VERSION ""

NS_ :

BS_:

BU_:

BO_ 2181387264 READ_PARAMETER_192_AND_193: 8 Vector__XXX
 SG_ FIRST_PARAMETER_VALUE : 0|32@1+ (1,0) [0|0] "" Vector__XXX
 SG_ SECOND_PARAMETER_VALUE : 32|32@1+ (1,0) [0|0] "" Vector__XXX

CM_ BO_ 2181387264 "Read parameter 192 and 193 at the same time. SPARK MAX does not currently support this in v25.0.0-prerelease.4";
CM_ SG_ 2181387264 FIRST_PARAMETER_VALUE "The actual type of this data depends on the Parameter Type of the parameter in question";
CM_ SG_ 2181387264 SECOND_PARAMETER_VALUE "The actual type of this data depends on the Parameter Type of the parameter in question";

BO_ 2181387328 READ_PARAMETER_194_AND_195: 8 Vector__XXX
 SG_ FIRST_PARAMETER_VALUE : 0|32@1+ (1,0) [0|0] "" Vector__XXX
 SG_ SECOND_PARAMETER_VALUE : 32|32@1+ (1,0) [0|0] "" Vector__XXX

CM_ BO_ 2181387328 "Read parameter 194 and 195 at the same time. SPARK MAX does not currently support this in v25.0.0-prerelease.4";
CM_ SG_ 2181387328 FIRST_PARAMETER_VALUE "The actual type of this data depends on the Parameter Type of the parameter in question";
CM_ SG_ 2181387328 SECOND_PARAMETER_VALUE "The actual type of this data depends on the Parameter Type of the parameter in question";

BO_ 2181387392 READ_PARAMETER_196_AND_197: 8 Vector__XXX
 SG_ FIRST_PARAMETER_VALUE : 0|32@1+ (1,0) [0|0] "" Vector__XXX
 SG_ SECOND_PARAMETER_VALUE : 32|32@1+ (1,0) [0|0] "" Vector__XXX

CM_ BO_ 2181387392 "Read parameter 196 and 197 at the same time. SPARK MAX does not currently support this in v25.0.0-prerelease.4";
CM_ SG_ 2181387392 FIRST_PARAMETER_VALUE "The actual type of this data depends on the Parameter Type of the parameter in question";
CM_ SG_ 2181387392 SECOND_PARAMETER_VALUE "The actual type of this data depends on the Parameter Type of the parameter in question";

BO_ 2181387456 READ_PARAMETER_198_AND_199: 8 Vector__XXX
 SG_ FIRST_PARAMETER_VALUE : 0|32@1+ (1,0) [0|0] "" Vector__XXX
 SG_ SECOND_PARAMETER_VALUE : 32|32@1+ (1,0) [0|0] "" Vector__XXX

CM_ BO_ 2181387456 "Read parameter 198 and 199 at the same time. SPARK MAX does not currently support this in v25.0.0-prerelease.4";
CM_ SG_ 2181387456 FIRST_PARAMETER_VALUE "The actual type of this data depends on the Parameter Type of the parameter in question";
CM_ SG_ 2181387456 SECOND_PARAMETER_VALUE "The actual type of this data depends on the Parameter Type of the parameter in question";

BO_ 2181387520 READ_PARAMETER_200_AND_201: 8 Vector__XXX
 SG_ FIRST_PARAMETER_VALUE : 0|32@1+ (1,0) [0|0] "" Vector__XXX
 SG_ SECOND_PARAMETER_VALUE : 32|32@1+ (1,0) [0|0] "" Vector__XXX

CM_ BO_ 2181387520 "Read parameter 200 and 201 at the same time. SPARK MAX does not currently support this in v25.0.0-prerelease.4";
CM_ SG_ 2181387520 FIRST_PARAMETER_VALUE "The actual type of this data depends on the Parameter Type of the parameter in question";
CM_ SG_ 2181387520 SECOND_PARAMETER_VALUE "The actual type of this data depends on the Parameter Type of the parameter in question";

BO_ 2181387584 READ_PARAMETER_202_AND_203: 8 Vector__XXX
 SG_ FIRST_PARAMETER_VALUE : 0|32@1+ (1,0) [0|0] "" Vector__XXX
 SG_ SECOND_PARAMETER_VALUE : 32|32@1+ (1,0) [0|0] "" Vector__XXX

CM_ BO_ 2181387584 "Read parameter 202 and 203 at the same time. SPARK MAX does not currently support this in v25.0.0-prerelease.4";
CM_ SG_ 2181387584 FIRST_PARAMETER_VALUE "The actual type of this data depends on the Parameter Type of the parameter in question";
CM_ SG_ 2181387584 SECOND_PARAMETER_VALUE "The actual type of this data depends on the Parameter Type of the parameter in question";

BO_ 2181387648 READ_PARAMETER_204_AND_205: 8 Vector__XXX
 SG_ FIRST_PARAMETER_VALUE : 0|32@1+ (1,0) [0|0] "" Vector__XXX
 SG_ SECOND_PARAMETER_VALUE : 32|32@1+ (1,0) [0|0] "" Vector__XXX

CM_ BO_ 2181387648 "Read parameter 204 and 205 at the same time. SPARK MAX does not currently support this in v25.0.0-prerelease.4";
CM_ SG_ 2181387648 FIRST_PARAMETER_VALUE "The actual type of this data depends on the Parameter Type of the parameter in question";
CM_ SG_ 2181387648 SECOND_PARAMETER_VALUE "The actual type of this data depends on the Parameter Type of the parameter in question";

BO_ 2181387712 READ_PARAMETER_206_AND_207: 8 Vector__XXX
 SG_ FIRST_PARAMETER_VALUE : 0|32@1+ (1,0) [0|0] "" Vector__XXX
 SG_ SECOND_PARAMETER_VALUE : 32|32@1+ (1,0) [0|0] "" Vector__XXX

CM_ BO_ 2181387712 "Read parameter 206 and 207 at the same time. SPARK MAX does not currently support this in v25.0.0-prerelease.4";
CM_ SG_ 2181387712 FIRST_PARAMETER_VALUE "The actual type of this data depends on the Parameter Type of the parameter in question";
CM_ SG_ 2181387712 SECOND_PARAMETER_VALUE "The actual type of this data depends on the Parameter Type of the parameter in question";

BO_ 2181387776 READ_PARAMETER_208_AND_209: 8 Vector__XXX
 SG_ FIRST_PARAMETER_VALUE : 0|32@1+ (1,0) [0|0] "" Vector__XXX
 SG_ SECOND_PARAMETER_VALUE : 32|32@1+ (1,0) [0|0] "" Vector__XXX

CM_ BO_ 2181387776 "Read parameter 208 and 209 at the same time. SPARK MAX does not currently support this in v25.0.0-prerelease.4";
CM_ SG_ 2181387776 FIRST_PARAMETER_VALUE "The actual type of this data depends on the Parameter Type of the parameter in question";
CM_ SG_ 2181387776 SECOND_PARAMETER_VALUE "The actual type of this data depends on the Parameter Type of the parameter in question";

BO_ 2181387840 READ_PARAMETER_210_AND_211: 8 Vector__XXX
 SG_ FIRST_PARAMETER_VALUE : 0|32@1+ (1,0) [0|0] "" Vector__XXX
 SG_ SECOND_PARAMETER_VALUE : 32|32@1+ (1,0) [0|0] "" Vector__XXX

CM_ BO_ 2181387840 "Read parameter 210 and 211 at the same time. SPARK MAX does not currently support this in v25.0.0-prerelease.4";
CM_ SG_ 2181387840 FIRST_PARAMETER_VALUE "The actual type of this data depends on the Parameter Type of the parameter in question";
CM_ SG_ 2181387840 SECOND_PARAMETER_VALUE "The actual type of this data depends on the Parameter Type of the parameter in question";

BO_ 2181387904 READ_PARAMETER_212_AND_213: 8 Vector__XXX
 SG_ FIRST_PARAMETER_VALUE : 0|32@1+ (1,0) [0|0] "" Vector__XXX
 SG_ SECOND_PARAMETER_VALUE : 32|32@1+ (1,0) [0|0] "" Vector__XXX

CM_ BO_ 2181387904 "Read parameter 212 and 213 at the same time. SPARK MAX does not currently support this in v25.0.0-prerelease.4";
CM_ SG_ 2181387904 FIRST_PARAMETER_VALUE "The actual type of this data depends on the Parameter Type of the parameter in question";
CM_ SG_ 2181387904 SECOND_PARAMETER_VALUE "The actual type of this data depends on the Parameter Type of the parameter in question";

BO_ 2181387968 READ_PARAMETER_214_AND_215: 8 Vector__XXX
 SG_ FIRST_PARAMETER_VALUE : 0|32@1+ (1,0) [0|0] "" Vector__XXX
 SG_ SECOND_PARAMETER_VALUE : 32|32@1+ (1,0) [0|0] "" Vector__XXX

CM_ BO_ 2181387968 "Read parameter 214 and 215 at the same time. SPARK MAX does not currently support this in v25.0.0-prerelease.4";
CM_ SG_ 2181387968 FIRST_PARAMETER_VALUE "The actual type of this data depends on the Parameter Type of the parameter in question";
CM_ SG_ 2181387968 SECOND_PARAMETER_VALUE "The actual type of this data depends on the Parameter Type of the parameter in question";

BO_ 2181388032 READ_PARAMETER_216_AND_217: 8 Vector__XXX
 SG_ FIRST_PARAMETER_VALUE : 0|32@1+ (1,0) [0|0] "" Vector__XXX
 SG_ SECOND_PARAMETER_VALUE : 32|32@1+ (1,0) [0|0] "" Vector__XXX

CM_ BO_ 2181388032 "Read parameter 216 and 217 at the same time. SPARK MAX does not currently support this in v25.0.0-prerelease.4";
CM_ SG_ 2181388032 FIRST_PARAMETER_VALUE "The actual type of this data depends on the Parameter Type of the parameter in question";
CM_ SG_ 2181388032 SECOND_PARAMETER_VALUE "The actual type of this data depends on the Parameter Type of the parameter in question";

BO_ 2181388096 READ_PARAMETER_218_AND_219: 8 Vector__XXX
 SG_ FIRST_PARAMETER_VALUE : 0|32@1+ (1,0) [0|0] "" Vector__XXX
 SG_ SECOND_PARAMETER_VALUE : 32|32@1+ (1,0) [0|0] "" Vector__XXX

CM_ BO_ 2181388096 "Read parameter 218 and 219 at the same time. SPARK MAX does not currently support this in v25.0.0-prerelease.4";
CM_ SG_ 2181388096 FIRST_PARAMETER_VALUE "The actual type of this data depends on the Parameter Type of the parameter in question";
CM_ SG_ 2181388096 SECOND_PARAMETER_VALUE "The actual type of this data depends on the Parameter Type of the parameter in question";

BO_ 2181388160 READ_PARAMETER_220_AND_221: 8 Vector__XXX
 SG_ FIRST_PARAMETER_VALUE : 0|32@1+ (1,0) [0|0] "" Vector__XXX
 SG_ SECOND_PARAMETER_VALUE : 32|32@1+ (1,0) [0|0] "" Vector__XXX

CM_ BO_ 2181388160 "Read parameter 220 and 221 at the same time. SPARK MAX does not currently support this in v25.0.0-prerelease.4";
CM_ SG_ 2181388160 FIRST_PARAMETER_VALUE "The actual type of this data depends on the Parameter Type of the parameter in question";
CM_ SG_ 2181388160 SECOND_PARAMETER_VALUE "The actual type of this data depends on the Parameter Type of the parameter in question";

BO_ 2181388224 READ_PARAMETER_222_AND_223: 8 Vector__XXX
 SG_ FIRST_PARAMETER_VALUE : 0|32@1+ (1,0) [0|0] "" Vector__XXX
 SG_ SECOND_PARAMETER_VALUE : 32|32@1+ (1,0) [0|0] "" Vector__XXX

CM_ BO_ 2181388224 "Read parameter 222 and 223 at the same time. SPARK MAX does not currently support this in v25.0.0-prerelease.4";
CM_ SG_ 2181388224 FIRST_PARAMETER_VALUE "The actual type of this data depends on the Parameter Type of the parameter in question";
CM_ SG_ 2181388224 SECOND_PARAMETER_VALUE "The actual type of this data depends on the Parameter Type of the parameter in question";

BO_ 2181388288 READ_PARAMETER_224_AND_225: 8 Vector__XXX
 SG_ FIRST_PARAMETER_VALUE : 0|32@1+ (1,0) [0|0] "" Vector__XXX
 SG_ SECOND_PARAMETER_VALUE : 32|32@1+ (1,0) [0|0] "" Vector__XXX

CM_ BO_ 2181388288 "Read parameter 224 and 225 at the same time. SPARK MAX does not currently support this in v25.0.0-prerelease.4";
CM_ SG_ 2181388288 FIRST_PARAMETER_VALUE "The actual type of this data depends on the Parameter Type of the parameter in question";
CM_ SG_ 2181388288 SECOND_PARAMETER_VALUE "The actual type of this data depends on the Parameter Type of the parameter in question";

BO_ 2181388352 READ_PARAMETER_226_AND_227: 8 Vector__XXX
 SG_ FIRST_PARAMETER_VALUE : 0|32@1+ (1,0) [0|0] "" Vector__XXX
 SG_ SECOND_PARAMETER_VALUE : 32|32@1+ (1,0) [0|0] "" Vector__XXX

CM_ BO_ 2181388352 "Read parameter 226 and 227 at the same time. SPARK MAX does not currently support this in v25.0.0-prerelease.4";
CM_ SG_ 2181388352 FIRST_PARAMETER_VALUE "The actual type of this data depends on the Parameter Type of the parameter in question";
CM_ SG_ 2181388352 SECOND_PARAMETER_VALUE "The actual type of this data depends on the Parameter Type of the parameter in question";

BO_ 2181388416 READ_PARAMETER_228_AND_229: 8 Vector__XXX
 SG_ FIRST_PARAMETER_VALUE : 0|32@1+ (1,0) [0|0] "" Vector__XXX
 SG_ SECOND_PARAMETER_VALUE : 32|32@1+ (1,0) [0|0] "" Vector__XXX

CM_ BO_ 2181388416 "Read parameter 228 and 229 at the same time. SPARK MAX does not currently support this in v25.0.0-prerelease.4";
CM_ SG_ 2181388416 FIRST_PARAMETER_VALUE "The actual type of this data depends on the Parameter Type of the parameter in question";
CM_ SG_ 2181388416 SECOND_PARAMETER_VALUE "The actual type of this data depends on the Parameter Type of the parameter in question";

BO_ 2181388480 READ_PARAMETER_230_AND_231: 8 Vector__XXX
 SG_ FIRST_PARAMETER_VALUE : 0|32@1+ (1,0) [0|0] "" Vector__XXX
 SG_ SECOND_PARAMETER_VALUE : 32|32@1+ (1,0) [0|0] "" Vector__XXX

CM_ BO_ 2181388480 "Read parameter 230 and 231 at the same time. SPARK MAX does not currently support this in v25.0.0-prerelease.4";
CM_ SG_ 2181388480 FIRST_PARAMETER_VALUE "The actual type of this data depends on the Parameter Type of the parameter in question";
CM_ SG_ 2181388480 SECOND_PARAMETER_VALUE "The actual type of this data depends on the Parameter Type of the parameter in question";

BO_ 2181388544 READ_PARAMETER_232_AND_233: 8 Vector__XXX
 SG_ FIRST_PARAMETER_VALUE : 0|32@1+ (1,0) [0|0] "" Vector__XXX
 SG_ SECOND_PARAMETER_VALUE : 32|32@1+ (1,0) [0|0] "" Vector__XXX

CM_ BO_ 2181388544 "Read parameter 232 and 233 at the same time. SPARK MAX does not currently support this in v25.0.0-prerelease.4";
CM_ SG_ 2181388544 FIRST_PARAMETER_VALUE "The actual type of this data depends on the Parameter Type of the parameter in question";
CM_ SG_ 2181388544 SECOND_PARAMETER_VALUE "The actual type of this data depends on the Parameter Type of the parameter in question";

BO_ 2181388608 READ_PARAMETER_234_AND_235: 8 Vector__XXX
 SG_ FIRST_PARAMETER_VALUE : 0|32@1+ (1,0) [0|0] "" Vector__XXX
 SG_ SECOND_PARAMETER_VALUE : 32|32@1+ (1,0) [0|0] "" Vector__XXX

CM_ BO_ 2181388608 "Read parameter 234 and 235 at the same time. SPARK MAX does not currently support this in v25.0.0-prerelease.4";
CM_ SG_ 2181388608 FIRST_PARAMETER_VALUE "The actual type of this data depends on the Parameter Type of the parameter in question";
CM_ SG_ 2181388608 SECOND_PARAMETER_VALUE "The actual type of this data depends on the Parameter Type of the parameter in question";

BO_ 2181388672 READ_PARAMETER_236_AND_237: 8 Vector__XXX
 SG_ FIRST_PARAMETER_VALUE : 0|32@1+ (1,0) [0|0] "" Vector__XXX
 SG_ SECOND_PARAMETER_VALUE : 32|32@1+ (1,0) [0|0] "" Vector__XXX

CM_ BO_ 2181388672 "Read parameter 236 and 237 at the same time. SPARK MAX does not currently support this in v25.0.0-prerelease.4";
CM_ SG_ 2181388672 FIRST_PARAMETER_VALUE "The actual type of this data depends on the Parameter Type of the parameter in question";
CM_ SG_ 2181388672 SECOND_PARAMETER_VALUE "The actual type of this data depends on the Parameter Type of the parameter in question";

BO_ 2181388736 READ_PARAMETER_238_AND_239: 8 Vector__XXX
 SG_ FIRST_PARAMETER_VALUE : 0|32@1+ (1,0) [0|0] "" Vector__XXX
 SG_ SECOND_PARAMETER_VALUE : 32|32@1+ (1,0) [0|0] "" Vector__XXX

CM_ BO_ 2181388736 "Read parameter 238 and 239 at the same time. SPARK MAX does not currently support this in v25.0.0-prerelease.4";
CM_ SG_ 2181388736 FIRST_PARAMETER_VALUE "The actual type of this data depends on the Parameter Type of the parameter in question";
CM_ SG_ 2181388736 SECOND_PARAMETER_VALUE "The actual type of this data depends on the Parameter Type of the parameter in question";

BO_ 2181388800 READ_PARAMETER_240_AND_241: 8 Vector__XXX
 SG_ FIRST_PARAMETER_VALUE : 0|32@1+ (1,0) [0|0] "" Vector__XXX
 SG_ SECOND_PARAMETER_VALUE : 32|32@1+ (1,0) [0|0] "" Vector__XXX

CM_ BO_ 2181388800 "Read parameter 240 and 241 at the same time. SPARK MAX does not currently support this in v25.0.0-prerelease.4";
CM_ SG_ 2181388800 FIRST_PARAMETER_VALUE "The actual type of this data depends on the Parameter Type of the parameter in question";
CM_ SG_ 2181388800 SECOND_PARAMETER_VALUE "The actual type of this data depends on the Parameter Type of the parameter in question";

BO_ 2181388864 READ_PARAMETER_242_AND_243: 8 Vector__XXX
 SG_ FIRST_PARAMETER_VALUE : 0|32@1+ (1,0) [0|0] "" Vector__XXX
 SG_ SECOND_PARAMETER_VALUE : 32|32@1+ (1,0) [0|0] "" Vector__XXX

CM_ BO_ 2181388864 "Read parameter 242 and 243 at the same time. SPARK MAX does not currently support this in v25.0.0-prerelease.4";
CM_ SG_ 2181388864 FIRST_PARAMETER_VALUE "The actual type of this data depends on the Parameter Type of the parameter in question";
CM_ SG_ 2181388864 SECOND_PARAMETER_VALUE "The actual type of this data depends on the Parameter Type of the parameter in question";

BO_ 2181388928 READ_PARAMETER_244_AND_245: 8 Vector__XXX
 SG_ FIRST_PARAMETER_VALUE : 0|32@1+ (1,0) [0|0] "" Vector__XXX
 SG_ SECOND_PARAMETER_VALUE : 32|32@1+ (1,0) [0|0] "" Vector__XXX

CM_ BO_ 2181388928 "Read parameter 244 and 245 at the same time. SPARK MAX does not currently support this in v25.0.0-prerelease.4";
CM_ SG_ 2181388928 FIRST_PARAMETER_VALUE "The actual type of this data depends on the Parameter Type of the parameter in question";
CM_ SG_ 2181388928 SECOND_PARAMETER_VALUE "The actual type of this data depends on the Parameter Type of the parameter in question";

BO_ 2181388992 READ_PARAMETER_246_AND_247: 8 Vector__XXX
 SG_ FIRST_PARAMETER_VALUE : 0|32@1+ (1,0) [0|0] "" Vector__XXX
 SG_ SECOND_PARAMETER_VALUE : 32|32@1+ (1,0) [0|0] "" Vector__XXX

CM_ BO_ 2181388992 "Read parameter 246 and 247 at the same time. SPARK MAX does not currently support this in v25.0.0-prerelease.4";
CM_ SG_ 2181388992 FIRST_PARAMETER_VALUE "The actual type of this data depends on the Parameter Type of the parameter in question";
CM_ SG_ 2181388992 SECOND_PARAMETER_VALUE "The actual type of this data depends on the Parameter Type of the parameter in question";

BO_ 2181389056 READ_PARAMETER_248_AND_249: 8 Vector__XXX
 SG_ FIRST_PARAMETER_VALUE : 0|32@1+ (1,0) [0|0] "" Vector__XXX
 SG_ SECOND_PARAMETER_VALUE : 32|32@1+ (1,0) [0|0] "" Vector__XXX

CM_ BO_ 2181389056 "Read parameter 248 and 249 at the same time. SPARK MAX does not currently support this in v25.0.0-prerelease.4";
CM_ SG_ 2181389056 FIRST_PARAMETER_VALUE "The actual type of this data depends on the Parameter Type of the parameter in question";
CM_ SG_ 2181389056 SECOND_PARAMETER_VALUE "The actual type of this data depends on the Parameter Type of the parameter in question";

BO_ 2181389120 READ_PARAMETER_250_AND_251: 8 Vector__XXX
 SG_ FIRST_PARAMETER_VALUE : 0|32@1+ (1,0) [0|0] "" Vector__XXX
 SG_ SECOND_PARAMETER_VALUE : 32|32@1+ (1,0) [0|0] "" Vector__XXX

CM_ BO_ 2181389120 "Read parameter 250 and 251 at the same time. SPARK MAX does not currently support this in v25.0.0-prerelease.4";
CM_ SG_ 2181389120 FIRST_PARAMETER_VALUE "The actual type of this data depends on the Parameter Type of the parameter in question";
CM_ SG_ 2181389120 SECOND_PARAMETER_VALUE "The actual type of this data depends on the Parameter Type of the parameter in question";

BO_ 2181389184 READ_PARAMETER_252_AND_253: 8 Vector__XXX
 SG_ FIRST_PARAMETER_VALUE : 0|32@1+ (1,0) [0|0] "" Vector__XXX
 SG_ SECOND_PARAMETER_VALUE : 32|32@1+ (1,0) [0|0] "" Vector__XXX

CM_ BO_ 2181389184 "Read parameter 252 and 253 at the same time. SPARK MAX does not currently support this in v25.0.0-prerelease.4";
CM_ SG_ 2181389184 FIRST_PARAMETER_VALUE "The actual type of this data depends on the Parameter Type of the parameter in question";
CM_ SG_ 2181389184 SECOND_PARAMETER_VALUE "The actual type of this data depends on the Parameter Type of the parameter in question";

BO_ 2181389248 READ_PARAMETER_254_AND_255: 8 Vector__XXX
 SG_ FIRST_PARAMETER_VALUE : 0|32@1+ (1,0) [0|0] "" Vector__XXX
 SG_ SECOND_PARAMETER_VALUE : 32|32@1+ (1,0) [0|0] "" Vector__XXX

CM_ BO_ 2181389248 "Read parameter 254 and 255 at the same time. SPARK MAX does not currently support this in v25.0.0-prerelease.4";
CM_ SG_ 2181389248 FIRST_PARAMETER_VALUE "The actual type of this data depends on the Parameter Type of the parameter in question";
CM_ SG_ 2181389248 SECOND_PARAMETER_VALUE "The actual type of this data depends on the Parameter Type of the parameter in question";

BO_ 2181389312 WRITE_PARAMETER_0_AND_1: 8 Vector__XXX
 SG_ FIRST_PARAMETER_VALUE : 0|32@1+ (1,0) [0|0] "" Vector__XXX
 SG_ SECOND_PARAMETER_VALUE : 32|32@1+ (1,0) [0|0] "" Vector__XXX

CM_ BO_ 2181389312 "Write Parameter 0 and 1 at the same time. Two Write Parameter Response frames will be sent in response.";
CM_ SG_ 2181389312 FIRST_PARAMETER_VALUE "The actual type of this data depends on the Parameter Type of the parameter in question";
CM_ SG_ 2181389312 SECOND_PARAMETER_VALUE "The actual type of this data depends on the Parameter Type of the parameter in question";

BO_ 2181389376 WRITE_PARAMETER_2_AND_3: 8 Vector__XXX
 SG_ FIRST_PARAMETER_VALUE : 0|32@1+ (1,0) [0|0] "" Vector__XXX
 SG_ SECOND_PARAMETER_VALUE : 32|32@1+ (1,0) [0|0] "" Vector__XXX

CM_ BO_ 2181389376 "Write Parameter 2 and 3 at the same time. Two Write Parameter Response frames will be sent in response.";
CM_ SG_ 2181389376 FIRST_PARAMETER_VALUE "The actual type of this data depends on the Parameter Type of the parameter in question";
CM_ SG_ 2181389376 SECOND_PARAMETER_VALUE "The actual type of this data depends on the Parameter Type of the parameter in question";

BO_ 2181389440 WRITE_PARAMETER_4_AND_5: 8 Vector__XXX
 SG_ FIRST_PARAMETER_VALUE : 0|32@1+ (1,0) [0|0] "" Vector__XXX
 SG_ SECOND_PARAMETER_VALUE : 32|32@1+ (1,0) [0|0] "" Vector__XXX

CM_ BO_ 2181389440 "Write Parameter 4 and 5 at the same time. Two Write Parameter Response frames will be sent in response.";
CM_ SG_ 2181389440 FIRST_PARAMETER_VALUE "The actual type of this data depends on the Parameter Type of the parameter in question";
CM_ SG_ 2181389440 SECOND_PARAMETER_VALUE "The actual type of this data depends on the Parameter Type of the parameter in question";

BO_ 2181389504 WRITE_PARAMETER_6_AND_7: 8 Vector__XXX
 SG_ FIRST_PARAMETER_VALUE : 0|32@1+ (1,0) [0|0] "" Vector__XXX
 SG_ SECOND_PARAMETER_VALUE : 32|32@1+ (1,0) [0|0] "" Vector__XXX

CM_ BO_ 2181389504 "Write Parameter 6 and 7 at the same time. Two Write Parameter Response frames will be sent in response.";
CM_ SG_ 2181389504 FIRST_PARAMETER_VALUE "The actual type of this data depends on the Parameter Type of the parameter in question";
CM_ SG_ 2181389504 SECOND_PARAMETER_VALUE "The actual type of this data depends on the Parameter Type of the parameter in question";

BO_ 2181389568 WRITE_PARAMETER_8_AND_9: 8 Vector__XXX
 SG_ FIRST_PARAMETER_VALUE : 0|32@1+ (1,0) [0|0] "" Vector__XXX
 SG_ SECOND_PARAMETER_VALUE : 32|32@1+ (1,0) [0|0] "" Vector__XXX

CM_ BO_ 2181389568 "Write Parameter 8 and 9 at the same time. Two Write Parameter Response frames will be sent in response.";
CM_ SG_ 2181389568 FIRST_PARAMETER_VALUE "The actual type of this data depends on the Parameter Type of the parameter in question";
CM_ SG_ 2181389568 SECOND_PARAMETER_VALUE "The actual type of this data depends on the Parameter Type of the parameter in question";

BO_ 2181389632 WRITE_PARAMETER_10_AND_11: 8 Vector__XXX
 SG_ FIRST_PARAMETER_VALUE : 0|32@1+ (1,0) [0|0] "" Vector__XXX
 SG_ SECOND_PARAMETER_VALUE : 32|32@1+ (1,0) [0|0] "" Vector__XXX

CM_ BO_ 2181389632 "Write Parameter 10 and 11 at the same time. Two Write Parameter Response frames will be sent in response.";
CM_ SG_ 2181389632 FIRST_PARAMETER_VALUE "The actual type of this data depends on the Parameter Type of the parameter in question";
CM_ SG_ 2181389632 SECOND_PARAMETER_VALUE "The actual type of this data depends on the Parameter Type of the parameter in question";

BO_ 2181389696 WRITE_PARAMETER_12_AND_13: 8 Vector__XXX
 SG_ FIRST_PARAMETER_VALUE : 0|32@1+ (1,0) [0|0] "" Vector__XXX
 SG_ SECOND_PARAMETER_VALUE : 32|32@1+ (1,0) [0|0] "" Vector__XXX

CM_ BO_ 2181389696 "Write Parameter 12 and 13 at the same time. Two Write Parameter Response frames will be sent in response.";
CM_ SG_ 2181389696 FIRST_PARAMETER_VALUE "The actual type of this data depends on the Parameter Type of the parameter in question";
CM_ SG_ 2181389696 SECOND_PARAMETER_VALUE "The actual type of this data depends on the Parameter Type of the parameter in question";

BO_ 2181389760 WRITE_PARAMETER_14_AND_15: 8 Vector__XXX
 SG_ FIRST_PARAMETER_VALUE : 0|32@1+ (1,0) [0|0] "" Vector__XXX
 SG_ SECOND_PARAMETER_VALUE : 32|32@1+ (1,0) [0|0] "" Vector__XXX

CM_ BO_ 2181389760 "Write Parameter 14 and 15 at the same time. Two Write Parameter Response frames will be sent in response.";
CM_ SG_ 2181389760 FIRST_PARAMETER_VALUE "The actual type of this data depends on the Parameter Type of the parameter in question";
CM_ SG_ 2181389760 SECOND_PARAMETER_VALUE "The actual type of this data depends on the Parameter Type of the parameter in question";

BO_ 2181389824 WRITE_PARAMETER_16_AND_17: 8 Vector__XXX
 SG_ FIRST_PARAMETER_VALUE : 0|32@1+ (1,0) [0|0] "" Vector__XXX
 SG_ SECOND_PARAMETER_VALUE : 32|32@1+ (1,0) [0|0] "" Vector__XXX

CM_ BO_ 2181389824 "Write Parameter 16 and 17 at the same time. Two Write Parameter Response frames will be sent in response.";
CM_ SG_ 2181389824 FIRST_PARAMETER_VALUE "The actual type of this data depends on the Parameter Type of the parameter in question";
CM_ SG_ 2181389824 SECOND_PARAMETER_VALUE "The actual type of this data depends on the Parameter Type of the parameter in question";

BO_ 2181389888 WRITE_PARAMETER_18_AND_19: 8 Vector__XXX
 SG_ FIRST_PARAMETER_VALUE : 0|32@1+ (1,0) [0|0] "" Vector__XXX
 SG_ SECOND_PARAMETER_VALUE : 32|32@1+ (1,0) [0|0] "" Vector__XXX

CM_ BO_ 2181389888 "Write Parameter 18 and 19 at the same time. Two Write Parameter Response frames will be sent in response.";
CM_ SG_ 2181389888 FIRST_PARAMETER_VALUE "The actual type of this data depends on the Parameter Type of the parameter in question";
CM_ SG_ 2181389888 SECOND_PARAMETER_VALUE "The actual type of this data depends on the Parameter Type of the parameter in question";

BO_ 2181389952 WRITE_PARAMETER_20_AND_21: 8 Vector__XXX
 SG_ FIRST_PARAMETER_VALUE : 0|32@1+ (1,0) [0|0] "" Vector__XXX
 SG_ SECOND_PARAMETER_VALUE : 32|32@1+ (1,0) [0|0] "" Vector__XXX

CM_ BO_ 2181389952 "Write Parameter 20 and 21 at the same time. Two Write Parameter Response frames will be sent in response.";
CM_ SG_ 2181389952 FIRST_PARAMETER_VALUE "The actual type of this data depends on the Parameter Type of the parameter in question";
CM_ SG_ 2181389952 SECOND_PARAMETER_VALUE "The actual type of this data depends on the Parameter Type of the parameter in question";

BO_ 2181390016 WRITE_PARAMETER_22_AND_23: 8 Vector__XXX
 SG_ FIRST_PARAMETER_VALUE : 0|32@1+ (1,0) [0|0] "" Vector__XXX
 SG_ SECOND_PARAMETER_VALUE : 32|32@1+ (1,0) [0|0] "" Vector__XXX

CM_ BO_ 2181390016 "Write Parameter 22 and 23 at the same time. Two Write Parameter Response frames will be sent in response.";
CM_ SG_ 2181390016 FIRST_PARAMETER_VALUE "The actual type of this data depends on the Parameter Type of the parameter in question";
CM_ SG_ 2181390016 SECOND_PARAMETER_VALUE "The actual type of this data depends on the Parameter Type of the parameter in question";

BO_ 2181390080 WRITE_PARAMETER_24_AND_25: 8 Vector__XXX
 SG_ FIRST_PARAMETER_VALUE : 0|32@1+ (1,0) [0|0] "" Vector__XXX
 SG_ SECOND_PARAMETER_VALUE : 32|32@1+ (1,0) [0|0] "" Vector__XXX

CM_ BO_ 2181390080 "Write Parameter 24 and 25 at the same time. Two Write Parameter Response frames will be sent in response.";
CM_ SG_ 2181390080 FIRST_PARAMETER_VALUE "The actual type of this data depends on the Parameter Type of the parameter in question";
CM_ SG_ 2181390080 SECOND_PARAMETER_VALUE "The actual type of this data depends on the Parameter Type of the parameter in question";

BO_ 2181390144 WRITE_PARAMETER_26_AND_27: 8 Vector__XXX
 SG_ FIRST_PARAMETER_VALUE : 0|32@1+ (1,0) [0|0] "" Vector__XXX
 SG_ SECOND_PARAMETER_VALUE : 32|32@1+ (1,0) [0|0] "" Vector__XXX

CM_ BO_ 2181390144 "Write Parameter 26 and 27 at the same time. Two Write Parameter Response frames will be sent in response.";
CM_ SG_ 2181390144 FIRST_PARAMETER_VALUE "The actual type of this data depends on the Parameter Type of the parameter in question";
CM_ SG_ 2181390144 SECOND_PARAMETER_VALUE "The actual type of this data depends on the Parameter Type of the parameter in question";

BO_ 2181390208 WRITE_PARAMETER_28_AND_29: 8 Vector__XXX
 SG_ FIRST_PARAMETER_VALUE : 0|32@1+ (1,0) [0|0] "" Vector__XXX
 SG_ SECOND_PARAMETER_VALUE : 32|32@1+ (1,0) [0|0] "" Vector__XXX

CM_ BO_ 2181390208 "Write Parameter 28 and 29 at the same time. Two Write Parameter Response frames will be sent in response.";
CM_ SG_ 2181390208 FIRST_PARAMETER_VALUE "The actual type of this data depends on the Parameter Type of the parameter in question";
CM_ SG_ 2181390208 SECOND_PARAMETER_VALUE "The actual type of this data depends on the Parameter Type of the parameter in question";

BO_ 2181390272 WRITE_PARAMETER_30_AND_31: 8 Vector__XXX
 SG_ FIRST_PARAMETER_VALUE : 0|32@1+ (1,0) [0|0] "" Vector__XXX
 SG_ SECOND_PARAMETER_VALUE : 32|32@1+ (1,0) [0|0] "" Vector__XXX

CM_ BO_ 2181390272 "Write Parameter 30 and 31 at the same time. Two Write Parameter Response frames will be sent in response.";
CM_ SG_ 2181390272 FIRST_PARAMETER_VALUE "The actual type of this data depends on the Parameter Type of the parameter in question";
CM_ SG_ 2181390272 SECOND_PARAMETER_VALUE "The actual type of this data depends on the Parameter Type of the parameter in question";

BO_ 2181390336 WRITE_PARAMETER_32_AND_33: 8 Vector__XXX
 SG_ FIRST_PARAMETER_VALUE : 0|32@1+ (1,0) [0|0] "" Vector__XXX
 SG_ SECOND_PARAMETER_VALUE : 32|32@1+ (1,0) [0|0] "" Vector__XXX

CM_ BO_ 2181390336 "Write Parameter 32 and 33 at the same time. Two Write Parameter Response frames will be sent in response.";
CM_ SG_ 2181390336 FIRST_PARAMETER_VALUE "The actual type of this data depends on the Parameter Type of the parameter in question";
CM_ SG_ 2181390336 SECOND_PARAMETER_VALUE "The actual type of this data depends on the Parameter Type of the parameter in question";

BO_ 2181390400 WRITE_PARAMETER_34_AND_35: 8 Vector__XXX
 SG_ FIRST_PARAMETER_VALUE : 0|32@1+ (1,0) [0|0] "" Vector__XXX
 SG_ SECOND_PARAMETER_VALUE : 32|32@1+ (1,0) [0|0] "" Vector__XXX

CM_ BO_ 2181390400 "Write Parameter 34 and 35 at the same time. Two Write Parameter Response frames will be sent in response.";
CM_ SG_ 2181390400 FIRST_PARAMETER_VALUE "The actual type of this data depends on the Parameter Type of the parameter in question";
CM_ SG_ 2181390400 SECOND_PARAMETER_VALUE "The actual type of this data depends on the Parameter Type of the parameter in question";

BO_ 2181390464 WRITE_PARAMETER_36_AND_37: 8 Vector__XXX
 SG_ FIRST_PARAMETER_VALUE : 0|32@1+ (1,0) [0|0] "" Vector__XXX
 SG_ SECOND_PARAMETER_VALUE : 32|32@1+ (1,0) [0|0] "" Vector__XXX

CM_ BO_ 2181390464 "Write Parameter 36 and 37 at the same time. Two Write Parameter Response frames will be sent in response.";
CM_ SG_ 2181390464 FIRST_PARAMETER_VALUE "The actual type of this data depends on the Parameter Type of the parameter in question";
CM_ SG_ 2181390464 SECOND_PARAMETER_VALUE "The actual type of this data depends on the Parameter Type of the parameter in question";

BO_ 2181390528 WRITE_PARAMETER_38_AND_39: 8 Vector__XXX
 SG_ FIRST_PARAMETER_VALUE : 0|32@1+ (1,0) [0|0] "" Vector__XXX
 SG_ SECOND_PARAMETER_VALUE : 32|32@1+ (1,0) [0|0] "" Vector__XXX

CM_ BO_ 2181390528 "Write Parameter 38 and 39 at the same time. Two Write Parameter Response frames will be sent in response.";
CM_ SG_ 2181390528 FIRST_PARAMETER_VALUE "The actual type of this data depends on the Parameter Type of the parameter in question";
CM_ SG_ 2181390528 SECOND_PARAMETER_VALUE "The actual type of this data depends on the Parameter Type of the parameter in question";

BO_ 2181390592 WRITE_PARAMETER_40_AND_41: 8 Vector__XXX
 SG_ FIRST_PARAMETER_VALUE : 0|32@1+ (1,0) [0|0] "" Vector__XXX
 SG_ SECOND_PARAMETER_VALUE : 32|32@1+ (1,0) [0|0] "" Vector__XXX

CM_ BO_ 2181390592 "Write Parameter 40 and 41 at the same time. Two Write Parameter Response frames will be sent in response.";
CM_ SG_ 2181390592 FIRST_PARAMETER_VALUE "The actual type of this data depends on the Parameter Type of the parameter in question";
CM_ SG_ 2181390592 SECOND_PARAMETER_VALUE "The actual type of this data depends on the Parameter Type of the parameter in question";

BO_ 2181390656 WRITE_PARAMETER_42_AND_43: 8 Vector__XXX
 SG_ FIRST_PARAMETER_VALUE : 0|32@1+ (1,0) [0|0] "" Vector__XXX
 SG_ SECOND_PARAMETER_VALUE : 32|32@1+ (1,0) [0|0] "" Vector__XXX

CM_ BO_ 2181390656 "Write Parameter 42 and 43 at the same time. Two Write Parameter Response frames will be sent in response.";
CM_ SG_ 2181390656 FIRST_PARAMETER_VALUE "The actual type of this data depends on the Parameter Type of the parameter in question";
CM_ SG_ 2181390656 SECOND_PARAMETER_VALUE "The actual type of this data depends on the Parameter Type of the parameter in question";

BO_ 2181390720 WRITE_PARAMETER_44_AND_45: 8 Vector__XXX
 SG_ FIRST_PARAMETER_VALUE : 0|32@1+ (1,0) [0|0] "" Vector__XXX
 SG_ SECOND_PARAMETER_VALUE : 32|32@1+ (1,0) [0|0] "" Vector__XXX

CM_ BO_ 2181390720 "Write Parameter 44 and 45 at the same time. Two Write Parameter Response frames will be sent in response.";
CM_ SG_ 2181390720 FIRST_PARAMETER_VALUE "The actual type of this data depends on the Parameter Type of the parameter in question";
CM_ SG_ 2181390720 SECOND_PARAMETER_VALUE "The actual type of this data depends on the Parameter Type of the parameter in question";

BO_ 2181390784 WRITE_PARAMETER_46_AND_47: 8 Vector__XXX
 SG_ FIRST_PARAMETER_VALUE : 0|32@1+ (1,0) [0|0] "" Vector__XXX
 SG_ SECOND_PARAMETER_VALUE : 32|32@1+ (1,0) [0|0] "" Vector__XXX

CM_ BO_ 2181390784 "Write Parameter 46 and 47 at the same time. Two Write Parameter Response frames will be sent in response.";
CM_ SG_ 2181390784 FIRST_PARAMETER_VALUE "The actual type of this data depends on the Parameter Type of the parameter in question";
CM_ SG_ 2181390784 SECOND_PARAMETER_VALUE "The actual type of this data depends on the Parameter Type of the parameter in question";

BO_ 2181390848 WRITE_PARAMETER_48_AND_49: 8 Vector__XXX
 SG_ FIRST_PARAMETER_VALUE : 0|32@1+ (1,0) [0|0] "" Vector__XXX
 SG_ SECOND_PARAMETER_VALUE : 32|32@1+ (1,0) [0|0] "" Vector__XXX

CM_ BO_ 2181390848 "Write Parameter 48 and 49 at the same time. Two Write Parameter Response frames will be sent in response.";
CM_ SG_ 2181390848 FIRST_PARAMETER_VALUE "The actual type of this data depends on the Parameter Type of the parameter in question";
CM_ SG_ 2181390848 SECOND_PARAMETER_VALUE "The actual type of this data depends on the Parameter Type of the parameter in question";

BO_ 2181390912 WRITE_PARAMETER_50_AND_51: 8 Vector__XXX
 SG_ FIRST_PARAMETER_VALUE : 0|32@1+ (1,0) [0|0] "" Vector__XXX
 SG_ SECOND_PARAMETER_VALUE : 32|32@1+ (1,0) [0|0] "" Vector__XXX

CM_ BO_ 2181390912 "Write Parameter 50 and 51 at the same time. Two Write Parameter Response frames will be sent in response.";
CM_ SG_ 2181390912 FIRST_PARAMETER_VALUE "The actual type of this data depends on the Parameter Type of the parameter in question";
CM_ SG_ 2181390912 SECOND_PARAMETER_VALUE "The actual type of this data depends on the Parameter Type of the parameter in question";

BO_ 2181390976 WRITE_PARAMETER_52_AND_53: 8 Vector__XXX
 SG_ FIRST_PARAMETER_VALUE : 0|32@1+ (1,0) [0|0] "" Vector__XXX
 SG_ SECOND_PARAMETER_VALUE : 32|32@1+ (1,0) [0|0] "" Vector__XXX

CM_ BO_ 2181390976 "Write Parameter 52 and 53 at the same time. Two Write Parameter Response frames will be sent in response.";
CM_ SG_ 2181390976 FIRST_PARAMETER_VALUE "The actual type of this data depends on the Parameter Type of the parameter in question";
CM_ SG_ 2181390976 SECOND_PARAMETER_VALUE "The actual type of this data depends on the Parameter Type of the parameter in question";

BO_ 2181391040 WRITE_PARAMETER_54_AND_55: 8 Vector__XXX
 SG_ FIRST_PARAMETER_VALUE : 0|32@1+ (1,0) [0|0] "" Vector__XXX
 SG_ SECOND_PARAMETER_VALUE : 32|32@1+ (1,0) [0|0] "" Vector__XXX

CM_ BO_ 2181391040 "Write Parameter 54 and 55 at the same time. Two Write Parameter Response frames will be sent in response.";
CM_ SG_ 2181391040 FIRST_PARAMETER_VALUE "The actual type of this data depends on the Parameter Type of the parameter in question";
CM_ SG_ 2181391040 SECOND_PARAMETER_VALUE "The actual type of this data depends on the Parameter Type of the parameter in question";

BO_ 2181391104 WRITE_PARAMETER_56_AND_57: 8 Vector__XXX
 SG_ FIRST_PARAMETER_VALUE : 0|32@1+ (1,0) [0|0] "" Vector__XXX
 SG_ SECOND_PARAMETER_VALUE : 32|32@1+ (1,0) [0|0] "" Vector__XXX

CM_ BO_ 2181391104 "Write Parameter 56 and 57 at the same time. Two Write Parameter Response frames will be sent in response.";
CM_ SG_ 2181391104 FIRST_PARAMETER_VALUE "The actual type of this data depends on the Parameter Type of the parameter in question";
CM_ SG_ 2181391104 SECOND_PARAMETER_VALUE "The actual type of this data depends on the Parameter Type of the parameter in question";

BO_ 2181391168 WRITE_PARAMETER_58_AND_59: 8 Vector__XXX
 SG_ FIRST_PARAMETER_VALUE : 0|32@1+ (1,0) [0|0] "" Vector__XXX
 SG_ SECOND_PARAMETER_VALUE : 32|32@1+ (1,0) [0|0] "" Vector__XXX

CM_ BO_ 2181391168 "Write Parameter 58 and 59 at the same time. Two Write Parameter Response frames will be sent in response.";
CM_ SG_ 2181391168 FIRST_PARAMETER_VALUE "The actual type of this data depends on the Parameter Type of the parameter in question";
CM_ SG_ 2181391168 SECOND_PARAMETER_VALUE "The actual type of this data depends on the Parameter Type of the parameter in question";

BO_ 2181391232 WRITE_PARAMETER_60_AND_61: 8 Vector__XXX
 SG_ FIRST_PARAMETER_VALUE : 0|32@1+ (1,0) [0|0] "" Vector__XXX
 SG_ SECOND_PARAMETER_VALUE : 32|32@1+ (1,0) [0|0] "" Vector__XXX

CM_ BO_ 2181391232 "Write Parameter 60 and 61 at the same time. Two Write Parameter Response frames will be sent in response.";
CM_ SG_ 2181391232 FIRST_PARAMETER_VALUE "The actual type of this data depends on the Parameter Type of the parameter in question";
CM_ SG_ 2181391232 SECOND_PARAMETER_VALUE "The actual type of this data depends on the Parameter Type of the parameter in question";

BO_ 2181391296 WRITE_PARAMETER_62_AND_63: 8 Vector__XXX
 SG_ FIRST_PARAMETER_VALUE : 0|32@1+ (1,0) [0|0] "" Vector__XXX
 SG_ SECOND_PARAMETER_VALUE : 32|32@1+ (1,0) [0|0] "" Vector__XXX

CM_ BO_ 2181391296 "Write Parameter 62 and 63 at the same time. Two Write Parameter Response frames will be sent in response.";
CM_ SG_ 2181391296 FIRST_PARAMETER_VALUE "The actual type of this data depends on the Parameter Type of the parameter in question";
CM_ SG_ 2181391296 SECOND_PARAMETER_VALUE "The actual type of this data depends on the Parameter Type of the parameter in question";

BO_ 2181391360 WRITE_PARAMETER_64_AND_65: 8 Vector__XXX
 SG_ FIRST_PARAMETER_VALUE : 0|32@1+ (1,0) [0|0] "" Vector__XXX
 SG_ SECOND_PARAMETER_VALUE : 32|32@1+ (1,0) [0|0] "" Vector__XXX

CM_ BO_ 2181391360 "Write Parameter 64 and 65 at the same time. Two Write Parameter Response frames will be sent in response.";
CM_ SG_ 2181391360 FIRST_PARAMETER_VALUE "The actual type of this data depends on the Parameter Type of the parameter in question";
CM_ SG_ 2181391360 SECOND_PARAMETER_VALUE "The actual type of this data depends on the Parameter Type of the parameter in question";

BO_ 2181391424 WRITE_PARAMETER_66_AND_67: 8 Vector__XXX
 SG_ FIRST_PARAMETER_VALUE : 0|32@1+ (1,0) [0|0] "" Vector__XXX
 SG_ SECOND_PARAMETER_VALUE : 32|32@1+ (1,0) [0|0] "" Vector__XXX

CM_ BO_ 2181391424 "Write Parameter 66 and 67 at the same time. Two Write Parameter Response frames will be sent in response.";
CM_ SG_ 2181391424 FIRST_PARAMETER_VALUE "The actual type of this data depends on the Parameter Type of the parameter in question";
CM_ SG_ 2181391424 SECOND_PARAMETER_VALUE "The actual type of this data depends on the Parameter Type of the parameter in question";

BO_ 2181391488 WRITE_PARAMETER_68_AND_69: 8 Vector__XXX
 SG_ FIRST_PARAMETER_VALUE : 0|32@1+ (1,0) [0|0] "" Vector__XXX
 SG_ SECOND_PARAMETER_VALUE : 32|32@1+ (1,0) [0|0] "" Vector__XXX

CM_ BO_ 2181391488 "Write Parameter 68 and 69 at the same time. Two Write Parameter Response frames will be sent in response.";
CM_ SG_ 2181391488 FIRST_PARAMETER_VALUE "The actual type of this data depends on the Parameter Type of the parameter in question";
CM_ SG_ 2181391488 SECOND_PARAMETER_VALUE "The actual type of this data depends on the Parameter Type of the parameter in question";

BO_ 2181391552 WRITE_PARAMETER_70_AND_71: 8 Vector__XXX
 SG_ FIRST_PARAMETER_VALUE : 0|32@1+ (1,0) [0|0] "" Vector__XXX
 SG_ SECOND_PARAMETER_VALUE : 32|32@1+ (1,0) [0|0] "" Vector__XXX

CM_ BO_ 2181391552 "Write Parameter 70 and 71 at the same time. Two Write Parameter Response frames will be sent in response.";
CM_ SG_ 2181391552 FIRST_PARAMETER_VALUE "The actual type of this data depends on the Parameter Type of the parameter in question";
CM_ SG_ 2181391552 SECOND_PARAMETER_VALUE "The actual type of this data depends on the Parameter Type of the parameter in question";

BO_ 2181391616 WRITE_PARAMETER_72_AND_73: 8 Vector__XXX
 SG_ FIRST_PARAMETER_VALUE : 0|32@1+ (1,0) [0|0] "" Vector__XXX
 SG_ SECOND_PARAMETER_VALUE : 32|32@1+ (1,0) [0|0] "" Vector__XXX

CM_ BO_ 2181391616 "Write Parameter 72 and 73 at the same time. Two Write Parameter Response frames will be sent in response.";
CM_ SG_ 2181391616 FIRST_PARAMETER_VALUE "The actual type of this data depends on the Parameter Type of the parameter in question";
CM_ SG_ 2181391616 SECOND_PARAMETER_VALUE "The actual type of this data depends on the Parameter Type of the parameter in question";

BO_ 2181391680 WRITE_PARAMETER_74_AND_75: 8 Vector__XXX
 SG_ FIRST_PARAMETER_VALUE : 0|32@1+ (1,0) [0|0] "" Vector__XXX
 SG_ SECOND_PARAMETER_VALUE : 32|32@1+ (1,0) [0|0] "" Vector__XXX

CM_ BO_ 2181391680 "Write Parameter 74 and 75 at the same time. Two Write Parameter Response frames will be sent in response.";
CM_ SG_ 2181391680 FIRST_PARAMETER_VALUE "The actual type of this data depends on the Parameter Type of the parameter in question";
CM_ SG_ 2181391680 SECOND_PARAMETER_VALUE "The actual type of this data depends on the Parameter Type of the parameter in question";

BO_ 2181391744 WRITE_PARAMETER_76_AND_77: 8 Vector__XXX
 SG_ FIRST_PARAMETER_VALUE : 0|32@1+ (1,0) [0|0] "" Vector__XXX
 SG_ SECOND_PARAMETER_VALUE : 32|32@1+ (1,0) [0|0] "" Vector__XXX

CM_ BO_ 2181391744 "Write Parameter 76 and 77 at the same time. Two Write Parameter Response frames will be sent in response.";
CM_ SG_ 2181391744 FIRST_PARAMETER_VALUE "The actual type of this data depends on the Parameter Type of the parameter in question";
CM_ SG_ 2181391744 SECOND_PARAMETER_VALUE "The actual type of this data depends on the Parameter Type of the parameter in question";

BO_ 2181391808 WRITE_PARAMETER_78_AND_79: 8 Vector__XXX
 SG_ FIRST_PARAMETER_VALUE : 0|32@1+ (1,0) [0|0] "" Vector__XXX
 SG_ SECOND_PARAMETER_VALUE : 32|32@1+ (1,0) [0|0] "" Vector__XXX

CM_ BO_ 2181391808 "Write Parameter 78 and 79 at the same time. Two Write Parameter Response frames will be sent in response.";
CM_ SG_ 2181391808 FIRST_PARAMETER_VALUE "The actual type of this data depends on the Parameter Type of the parameter in question";
CM_ SG_ 2181391808 SECOND_PARAMETER_VALUE "The actual type of this data depends on the Parameter Type of the parameter in question";

BO_ 2181391872 WRITE_PARAMETER_80_AND_81: 8 Vector__XXX
 SG_ FIRST_PARAMETER_VALUE : 0|32@1+ (1,0) [0|0] "" Vector__XXX
 SG_ SECOND_PARAMETER_VALUE : 32|32@1+ (1,0) [0|0] "" Vector__XXX

CM_ BO_ 2181391872 "Write Parameter 80 and 81 at the same time. Two Write Parameter Response frames will be sent in response.";
CM_ SG_ 2181391872 FIRST_PARAMETER_VALUE "The actual type of this data depends on the Parameter Type of the parameter in question";
CM_ SG_ 2181391872 SECOND_PARAMETER_VALUE "The actual type of this data depends on the Parameter Type of the parameter in question";

BO_ 2181391936 WRITE_PARAMETER_82_AND_83: 8 Vector__XXX
 SG_ FIRST_PARAMETER_VALUE : 0|32@1+ (1,0) [0|0] "" Vector__XXX
 SG_ SECOND_PARAMETER_VALUE : 32|32@1+ (1,0) [0|0] "" Vector__XXX

CM_ BO_ 2181391936 "Write Parameter 82 and 83 at the same time. Two Write Parameter Response frames will be sent in response.";
CM_ SG_ 2181391936 FIRST_PARAMETER_VALUE "The actual type of this data depends on the Parameter Type of the parameter in question";
CM_ SG_ 2181391936 SECOND_PARAMETER_VALUE "The actual type of this data depends on the Parameter Type of the parameter in question";

BO_ 2181392000 WRITE_PARAMETER_84_AND_85: 8 Vector__XXX
 SG_ FIRST_PARAMETER_VALUE : 0|32@1+ (1,0) [0|0] "" Vector__XXX
 SG_ SECOND_PARAMETER_VALUE : 32|32@1+ (1,0) [0|0] "" Vector__XXX

CM_ BO_ 2181392000 "Write Parameter 84 and 85 at the same time. Two Write Parameter Response frames will be sent in response.";
CM_ SG_ 2181392000 FIRST_PARAMETER_VALUE "The actual type of this data depends on the Parameter Type of the parameter in question";
CM_ SG_ 2181392000 SECOND_PARAMETER_VALUE "The actual type of this data depends on the Parameter Type of the parameter in question";

BO_ 2181392064 WRITE_PARAMETER_86_AND_87: 8 Vector__XXX
 SG_ FIRST_PARAMETER_VALUE : 0|32@1+ (1,0) [0|0] "" Vector__XXX
 SG_ SECOND_PARAMETER_VALUE : 32|32@1+ (1,0) [0|0] "" Vector__XXX

CM_ BO_ 2181392064 "Write Parameter 86 and 87 at the same time. Two Write Parameter Response frames will be sent in response.";
CM_ SG_ 2181392064 FIRST_PARAMETER_VALUE "The actual type of this data depends on the Parameter Type of the parameter in question";
CM_ SG_ 2181392064 SECOND_PARAMETER_VALUE "The actual type of this data depends on the Parameter Type of the parameter in question";

BO_ 2181392128 WRITE_PARAMETER_88_AND_89: 8 Vector__XXX
 SG_ FIRST_PARAMETER_VALUE : 0|32@1+ (1,0) [0|0] "" Vector__XXX
 SG_ SECOND_PARAMETER_VALUE : 32|32@1+ (1,0) [0|0] "" Vector__XXX

CM_ BO_ 2181392128 "Write Parameter 88 and 89 at the same time. Two Write Parameter Response frames will be sent in response.";
CM_ SG_ 2181392128 FIRST_PARAMETER_VALUE "The actual type of this data depends on the Parameter Type of the parameter in question";
CM_ SG_ 2181392128 SECOND_PARAMETER_VALUE "The actual type of this data depends on the Parameter Type of the parameter in question";

BO_ 2181392192 WRITE_PARAMETER_90_AND_91: 8 Vector__XXX
 SG_ FIRST_PARAMETER_VALUE : 0|32@1+ (1,0) [0|0] "" Vector__XXX
 SG_ SECOND_PARAMETER_VALUE : 32|32@1+ (1,0) [0|0] "" Vector__XXX

CM_ BO_ 2181392192 "Write Parameter 90 and 91 at the same time. Two Write Parameter Response frames will be sent in response.";
CM_ SG_ 2181392192 FIRST_PARAMETER_VALUE "The actual type of this data depends on the Parameter Type of the parameter in question";
CM_ SG_ 2181392192 SECOND_PARAMETER_VALUE "The actual type of this data depends on the Parameter Type of the parameter in question";

BO_ 2181392256 WRITE_PARAMETER_92_AND_93: 8 Vector__XXX
 SG_ FIRST_PARAMETER_VALUE : 0|32@1+ (1,0) [0|0] "" Vector__XXX
 SG_ SECOND_PARAMETER_VALUE : 32|32@1+ (1,0) [0|0] "" Vector__XXX

CM_ BO_ 2181392256 "Write Parameter 92 and 93 at the same time. Two Write Parameter Response frames will be sent in response.";
CM_ SG_ 2181392256 FIRST_PARAMETER_VALUE "The actual type of this data depends on the Parameter Type of the parameter in question";
CM_ SG_ 2181392256 SECOND_PARAMETER_VALUE "The actual type of this data depends on the Parameter Type of the parameter in question";

BO_ 2181392320 WRITE_PARAMETER_94_AND_95: 8 Vector__XXX
 SG_ FIRST_PARAMETER_VALUE : 0|32@1+ (1,0) [0|0] "" Vector__XXX
 SG_ SECOND_PARAMETER_VALUE : 32|32@1+ (1,0) [0|0] "" Vector__XXX

CM_ BO_ 2181392320 "Write Parameter 94 and 95 at the same time. Two Write Parameter Response frames will be sent in response.";
CM_ SG_ 2181392320 FIRST_PARAMETER_VALUE "The actual type of this data depends on the Parameter Type of the parameter in question";
CM_ SG_ 2181392320 SECOND_PARAMETER_VALUE "The actual type of this data depends on the Parameter Type of the parameter in question";

BO_ 2181392384 WRITE_PARAMETER_96_AND_97: 8 Vector__XXX
 SG_ FIRST_PARAMETER_VALUE : 0|32@1+ (1,0) [0|0] "" Vector__XXX
 SG_ SECOND_PARAMETER_VALUE : 32|32@1+ (1,0) [0|0] "" Vector__XXX

CM_ BO_ 2181392384 "Write Parameter 96 and 97 at the same time. Two Write Parameter Response frames will be sent in response.";
CM_ SG_ 2181392384 FIRST_PARAMETER_VALUE "The actual type of this data depends on the Parameter Type of the parameter in question";
CM_ SG_ 2181392384 SECOND_PARAMETER_VALUE "The actual type of this data depends on the Parameter Type of the parameter in question";

BO_ 2181392448 WRITE_PARAMETER_98_AND_99: 8 Vector__XXX
 SG_ FIRST_PARAMETER_VALUE : 0|32@1+ (1,0) [0|0] "" Vector__XXX
 SG_ SECOND_PARAMETER_VALUE : 32|32@1+ (1,0) [0|0] "" Vector__XXX

CM_ BO_ 2181392448 "Write Parameter 98 and 99 at the same time. Two Write Parameter Response frames will be sent in response.";
CM_ SG_ 2181392448 FIRST_PARAMETER_VALUE "The actual type of this data depends on the Parameter Type of the parameter in question";
CM_ SG_ 2181392448 SECOND_PARAMETER_VALUE "The actual type of this data depends on the Parameter Type of the parameter in question";

BO_ 2181392512 WRITE_PARAMETER_100_AND_101: 8 Vector__XXX
 SG_ FIRST_PARAMETER_VALUE : 0|32@1+ (1,0) [0|0] "" Vector__XXX
 SG_ SECOND_PARAMETER_VALUE : 32|32@1+ (1,0) [0|0] "" Vector__XXX

CM_ BO_ 2181392512 "Write Parameter 100 and 101 at the same time. Two Write Parameter Response frames will be sent in response.";
CM_ SG_ 2181392512 FIRST_PARAMETER_VALUE "The actual type of this data depends on the Parameter Type of the parameter in question";
CM_ SG_ 2181392512 SECOND_PARAMETER_VALUE "The actual type of this data depends on the Parameter Type of the parameter in question";

BO_ 2181392576 WRITE_PARAMETER_102_AND_103: 8 Vector__XXX
 SG_ FIRST_PARAMETER_VALUE : 0|32@1+ (1,0) [0|0] "" Vector__XXX
 SG_ SECOND_PARAMETER_VALUE : 32|32@1+ (1,0) [0|0] "" Vector__XXX

CM_ BO_ 2181392576 "Write Parameter 102 and 103 at the same time. Two Write Parameter Response frames will be sent in response.";
CM_ SG_ 2181392576 FIRST_PARAMETER_VALUE "The actual type of this data depends on the Parameter Type of the parameter in question";
CM_ SG_ 2181392576 SECOND_PARAMETER_VALUE "The actual type of this data depends on the Parameter Type of the parameter in question";

BO_ 2181392640 WRITE_PARAMETER_104_AND_105: 8 Vector__XXX
 SG_ FIRST_PARAMETER_VALUE : 0|32@1+ (1,0) [0|0] "" Vector__XXX
 SG_ SECOND_PARAMETER_VALUE : 32|32@1+ (1,0) [0|0] "" Vector__XXX

CM_ BO_ 2181392640 "Write Parameter 104 and 105 at the same time. Two Write Parameter Response frames will be sent in response.";
CM_ SG_ 2181392640 FIRST_PARAMETER_VALUE "The actual type of this data depends on the Parameter Type of the parameter in question";
CM_ SG_ 2181392640 SECOND_PARAMETER_VALUE "The actual type of this data depends on the Parameter Type of the parameter in question";

BO_ 2181392704 WRITE_PARAMETER_106_AND_107: 8 Vector__XXX
 SG_ FIRST_PARAMETER_VALUE : 0|32@1+ (1,0) [0|0] "" Vector__XXX
 SG_ SECOND_PARAMETER_VALUE : 32|32@1+ (1,0) [0|0] "" Vector__XXX

CM_ BO_ 2181392704 "Write Parameter 106 and 107 at the same time. Two Write Parameter Response frames will be sent in response.";
CM_ SG_ 2181392704 FIRST_PARAMETER_VALUE "The actual type of this data depends on the Parameter Type of the parameter in question";
CM_ SG_ 2181392704 SECOND_PARAMETER_VALUE "The actual type of this data depends on the Parameter Type of the parameter in question";

BO_ 2181392768 WRITE_PARAMETER_108_AND_109: 8 Vector__XXX
 SG_ FIRST_PARAMETER_VALUE : 0|32@1+ (1,0) [0|0] "" Vector__XXX
 SG_ SECOND_PARAMETER_VALUE : 32|32@1+ (1,0) [0|0] "" Vector__XXX

CM_ BO_ 2181392768 "Write Parameter 108 and 109 at the same time. Two Write Parameter Response frames will be sent in response.";
CM_ SG_ 2181392768 FIRST_PARAMETER_VALUE "The actual type of this data depends on the Parameter Type of the parameter in question";
CM_ SG_ 2181392768 SECOND_PARAMETER_VALUE "The actual type of this data depends on the Parameter Type of the parameter in question";

BO_ 2181392832 WRITE_PARAMETER_110_AND_111: 8 Vector__XXX
 SG_ FIRST_PARAMETER_VALUE : 0|32@1+ (1,0) [0|0] "" Vector__XXX
 SG_ SECOND_PARAMETER_VALUE : 32|32@1+ (1,0) [0|0] "" Vector__XXX

CM_ BO_ 2181392832 "Write Parameter 110 and 111 at the same time. Two Write Parameter Response frames will be sent in response.";
CM_ SG_ 2181392832 FIRST_PARAMETER_VALUE "The actual type of this data depends on the Parameter Type of the parameter in question";
CM_ SG_ 2181392832 SECOND_PARAMETER_VALUE "The actual type of this data depends on the Parameter Type of the parameter in question";

BO_ 2181392896 WRITE_PARAMETER_112_AND_113: 8 Vector__XXX
 SG_ FIRST_PARAMETER_VALUE : 0|32@1+ (1,0) [0|0] "" Vector__XXX
 SG_ SECOND_PARAMETER_VALUE : 32|32@1+ (1,0) [0|0] "" Vector__XXX

CM_ BO_ 2181392896 "Write Parameter 112 and 113 at the same time. Two Write Parameter Response frames will be sent in response.";
CM_ SG_ 2181392896 FIRST_PARAMETER_VALUE "The actual type of this data depends on the Parameter Type of the parameter in question";
CM_ SG_ 2181392896 SECOND_PARAMETER_VALUE "The actual type of this data depends on the Parameter Type of the parameter in question";

BO_ 2181392960 WRITE_PARAMETER_114_AND_115: 8 Vector__XXX
 SG_ FIRST_PARAMETER_VALUE : 0|32@1+ (1,0) [0|0] "" Vector__XXX
 SG_ SECOND_PARAMETER_VALUE : 32|32@1+ (1,0) [0|0] "" Vector__XXX

CM_ BO_ 2181392960 "Write Parameter 114 and 115 at the same time. Two Write Parameter Response frames will be sent in response.";
CM_ SG_ 2181392960 FIRST_PARAMETER_VALUE "The actual type of this data depends on the Parameter Type of the parameter in question";
CM_ SG_ 2181392960 SECOND_PARAMETER_VALUE "The actual type of this data depends on the Parameter Type of the parameter in question";

BO_ 2181393024 WRITE_PARAMETER_116_AND_117: 8 Vector__XXX
 SG_ FIRST_PARAMETER_VALUE : 0|32@1+ (1,0) [0|0] "" Vector__XXX
 SG_ SECOND_PARAMETER_VALUE : 32|32@1+ (1,0) [0|0] "" Vector__XXX

CM_ BO_ 2181393024 "Write Parameter 116 and 117 at the same time. Two Write Parameter Response frames will be sent in response.";
CM_ SG_ 2181393024 FIRST_PARAMETER_VALUE "The actual type of this data depends on the Parameter Type of the parameter in question";
CM_ SG_ 2181393024 SECOND_PARAMETER_VALUE "The actual type of this data depends on the Parameter Type of the parameter in question";

BO_ 2181393088 WRITE_PARAMETER_118_AND_119: 8 Vector__XXX
 SG_ FIRST_PARAMETER_VALUE : 0|32@1+ (1,0) [0|0] "" Vector__XXX
 SG_ SECOND_PARAMETER_VALUE : 32|32@1+ (1,0) [0|0] "" Vector__XXX

CM_ BO_ 2181393088 "Write Parameter 118 and 119 at the same time. Two Write Parameter Response frames will be sent in response.";
CM_ SG_ 2181393088 FIRST_PARAMETER_VALUE "The actual type of this data depends on the Parameter Type of the parameter in question";
CM_ SG_ 2181393088 SECOND_PARAMETER_VALUE "The actual type of this data depends on the Parameter Type of the parameter in question";

BO_ 2181393152 WRITE_PARAMETER_120_AND_121: 8 Vector__XXX
 SG_ FIRST_PARAMETER_VALUE : 0|32@1+ (1,0) [0|0] "" Vector__XXX
 SG_ SECOND_PARAMETER_VALUE : 32|32@1+ (1,0) [0|0] "" Vector__XXX

CM_ BO_ 2181393152 "Write Parameter 120 and 121 at the same time. Two Write Parameter Response frames will be sent in response.";
CM_ SG_ 2181393152 FIRST_PARAMETER_VALUE "The actual type of this data depends on the Parameter Type of the parameter in question";
CM_ SG_ 2181393152 SECOND_PARAMETER_VALUE "The actual type of this data depends on the Parameter Type of the parameter in question";

BO_ 2181393216 WRITE_PARAMETER_122_AND_123: 8 Vector__XXX
 SG_ FIRST_PARAMETER_VALUE : 0|32@1+ (1,0) [0|0] "" Vector__XXX
 SG_ SECOND_PARAMETER_VALUE : 32|32@1+ (1,0) [0|0] "" Vector__XXX

CM_ BO_ 2181393216 "Write Parameter 122 and 123 at the same time. Two Write Parameter Response frames will be sent in response.";
CM_ SG_ 2181393216 FIRST_PARAMETER_VALUE "The actual type of this data depends on the Parameter Type of the parameter in question";
CM_ SG_ 2181393216 SECOND_PARAMETER_VALUE "The actual type of this data depends on the Parameter Type of the parameter in question";

BO_ 2181393280 WRITE_PARAMETER_124_AND_125: 8 Vector__XXX
 SG_ FIRST_PARAMETER_VALUE : 0|32@1+ (1,0) [0|0] "" Vector__XXX
 SG_ SECOND_PARAMETER_VALUE : 32|32@1+ (1,0) [0|0] "" Vector__XXX

CM_ BO_ 2181393280 "Write Parameter 124 and 125 at the same time. Two Write Parameter Response frames will be sent in response.";
CM_ SG_ 2181393280 FIRST_PARAMETER_VALUE "The actual type of this data depends on the Parameter Type of the parameter in question";
CM_ SG_ 2181393280 SECOND_PARAMETER_VALUE "The actual type of this data depends on the Parameter Type of the parameter in question";

BO_ 2181393344 WRITE_PARAMETER_126_AND_127: 8 Vector__XXX
 SG_ FIRST_PARAMETER_VALUE : 0|32@1+ (1,0) [0|0] "" Vector__XXX
 SG_ SECOND_PARAMETER_VALUE : 32|32@1+ (1,0) [0|0] "" Vector__XXX

CM_ BO_ 2181393344 "Write Parameter 126 and 127 at the same time. Two Write Parameter Response frames will be sent in response.";
CM_ SG_ 2181393344 FIRST_PARAMETER_VALUE "The actual type of this data depends on the Parameter Type of the parameter in question";
CM_ SG_ 2181393344 SECOND_PARAMETER_VALUE "The actual type of this data depends on the Parameter Type of the parameter in question";

BO_ 2181393408 WRITE_PARAMETER_128_AND_129: 8 Vector__XXX
 SG_ FIRST_PARAMETER_VALUE : 0|32@1+ (1,0) [0|0] "" Vector__XXX
 SG_ SECOND_PARAMETER_VALUE : 32|32@1+ (1,0) [0|0] "" Vector__XXX

CM_ BO_ 2181393408 "Write Parameter 128 and 129 at the same time. Two Write Parameter Response frames will be sent in response.";
CM_ SG_ 2181393408 FIRST_PARAMETER_VALUE "The actual type of this data depends on the Parameter Type of the parameter in question";
CM_ SG_ 2181393408 SECOND_PARAMETER_VALUE "The actual type of this data depends on the Parameter Type of the parameter in question";

BO_ 2181393472 WRITE_PARAMETER_130_AND_131: 8 Vector__XXX
 SG_ FIRST_PARAMETER_VALUE : 0|32@1+ (1,0) [0|0] "" Vector__XXX
 SG_ SECOND_PARAMETER_VALUE : 32|32@1+ (1,0) [0|0] "" Vector__XXX

CM_ BO_ 2181393472 "Write Parameter 130 and 131 at the same time. Two Write Parameter Response frames will be sent in response.";
CM_ SG_ 2181393472 FIRST_PARAMETER_VALUE "The actual type of this data depends on the Parameter Type of the parameter in question";
CM_ SG_ 2181393472 SECOND_PARAMETER_VALUE "The actual type of this data depends on the Parameter Type of the parameter in question";

BO_ 2181393536 WRITE_PARAMETER_132_AND_133: 8 Vector__XXX
 SG_ FIRST_PARAMETER_VALUE : 0|32@1+ (1,0) [0|0] "" Vector__XXX
 SG_ SECOND_PARAMETER_VALUE : 32|32@1+ (1,0) [0|0] "" Vector__XXX

CM_ BO_ 2181393536 "Write Parameter 132 and 133 at the same time. Two Write Parameter Response frames will be sent in response.";
CM_ SG_ 2181393536 FIRST_PARAMETER_VALUE "The actual type of this data depends on the Parameter Type of the parameter in question";
CM_ SG_ 2181393536 SECOND_PARAMETER_VALUE "The actual type of this data depends on the Parameter Type of the parameter in question";

BO_ 2181393600 WRITE_PARAMETER_134_AND_135: 8 Vector__XXX
 SG_ FIRST_PARAMETER_VALUE : 0|32@1+ (1,0) [0|0] "" Vector__XXX
 SG_ SECOND_PARAMETER_VALUE : 32|32@1+ (1,0) [0|0] "" Vector__XXX

CM_ BO_ 2181393600 "Write Parameter 134 and 135 at the same time. Two Write Parameter Response frames will be sent in response.";
CM_ SG_ 2181393600 FIRST_PARAMETER_VALUE "The actual type of this data depends on the Parameter Type of the parameter in question";
CM_ SG_ 2181393600 SECOND_PARAMETER_VALUE "The actual type of this data depends on the Parameter Type of the parameter in question";

BO_ 2181393664 WRITE_PARAMETER_136_AND_137: 8 Vector__XXX
 SG_ FIRST_PARAMETER_VALUE : 0|32@1+ (1,0) [0|0] "" Vector__XXX
 SG_ SECOND_PARAMETER_VALUE : 32|32@1+ (1,0) [0|0] "" Vector__XXX

CM_ BO_ 2181393664 "Write Parameter 136 and 137 at the same time. Two Write Parameter Response frames will be sent in response.";
CM_ SG_ 2181393664 FIRST_PARAMETER_VALUE "The actual type of this data depends on the Parameter Type of the parameter in question";
CM_ SG_ 2181393664 SECOND_PARAMETER_VALUE "The actual type of this data depends on the Parameter Type of the parameter in question";

BO_ 2181393728 WRITE_PARAMETER_138_AND_139: 8 Vector__XXX
 SG_ FIRST_PARAMETER_VALUE : 0|32@1+ (1,0) [0|0] "" Vector__XXX
 SG_ SECOND_PARAMETER_VALUE : 32|32@1+ (1,0) [0|0] "" Vector__XXX

CM_ BO_ 2181393728 "Write Parameter 138 and 139 at the same time. Two Write Parameter Response frames will be sent in response.";
CM_ SG_ 2181393728 FIRST_PARAMETER_VALUE "The actual type of this data depends on the Parameter Type of the parameter in question";
CM_ SG_ 2181393728 SECOND_PARAMETER_VALUE "The actual type of this data depends on the Parameter Type of the parameter in question";

BO_ 2181393792 WRITE_PARAMETER_140_AND_141: 8 Vector__XXX
 SG_ FIRST_PARAMETER_VALUE : 0|32@1+ (1,0) [0|0] "" Vector__XXX
 SG_ SECOND_PARAMETER_VALUE : 32|32@1+ (1,0) [0|0] "" Vector__XXX

CM_ BO_ 2181393792 "Write Parameter 140 and 141 at the same time. Two Write Parameter Response frames will be sent in response.";
CM_ SG_ 2181393792 FIRST_PARAMETER_VALUE "The actual type of this data depends on the Parameter Type of the parameter in question";
CM_ SG_ 2181393792 SECOND_PARAMETER_VALUE "The actual type of this data depends on the Parameter Type of the parameter in question";

BO_ 2181393856 WRITE_PARAMETER_142_AND_143: 8 Vector__XXX
 SG_ FIRST_PARAMETER_VALUE : 0|32@1+ (1,0) [0|0] "" Vector__XXX
 SG_ SECOND_PARAMETER_VALUE : 32|32@1+ (1,0) [0|0] "" Vector__XXX

CM_ BO_ 2181393856 "Write Parameter 142 and 143 at the same time. Two Write Parameter Response frames will be sent in response.";
CM_ SG_ 2181393856 FIRST_PARAMETER_VALUE "The actual type of this data depends on the Parameter Type of the parameter in question";
CM_ SG_ 2181393856 SECOND_PARAMETER_VALUE "The actual type of this data depends on the Parameter Type of the parameter in question";

BO_ 2181393920 WRITE_PARAMETER_144_AND_145: 8 Vector__XXX
 SG_ FIRST_PARAMETER_VALUE : 0|32@1+ (1,0) [0|0] "" Vector__XXX
 SG_ SECOND_PARAMETER_VALUE : 32|32@1+ (1,0) [0|0] "" Vector__XXX

CM_ BO_ 2181393920 "Write Parameter 144 and 145 at the same time. Two Write Parameter Response frames will be sent in response.";
CM_ SG_ 2181393920 FIRST_PARAMETER_VALUE "The actual type of this data depends on the Parameter Type of the parameter in question";
CM_ SG_ 2181393920 SECOND_PARAMETER_VALUE "The actual type of this data depends on the Parameter Type of the parameter in question";

BO_ 2181393984 WRITE_PARAMETER_146_AND_147: 8 Vector__XXX
 SG_ FIRST_PARAMETER_VALUE : 0|32@1+ (1,0) [0|0] "" Vector__XXX
 SG_ SECOND_PARAMETER_VALUE : 32|32@1+ (1,0) [0|0] "" Vector__XXX

CM_ BO_ 2181393984 "Write Parameter 146 and 147 at the same time. Two Write Parameter Response frames will be sent in response.";
CM_ SG_ 2181393984 FIRST_PARAMETER_VALUE "The actual type of this data depends on the Parameter Type of the parameter in question";
CM_ SG_ 2181393984 SECOND_PARAMETER_VALUE "The actual type of this data depends on the Parameter Type of the parameter in question";

BO_ 2181394048 WRITE_PARAMETER_148_AND_149: 8 Vector__XXX
 SG_ FIRST_PARAMETER_VALUE : 0|32@1+ (1,0) [0|0] "" Vector__XXX
 SG_ SECOND_PARAMETER_VALUE : 32|32@1+ (1,0) [0|0] "" Vector__XXX

CM_ BO_ 2181394048 "Write Parameter 148 and 149 at the same time. Two Write Parameter Response frames will be sent in response.";
CM_ SG_ 2181394048 FIRST_PARAMETER_VALUE "The actual type of this data depends on the Parameter Type of the parameter in question";
CM_ SG_ 2181394048 SECOND_PARAMETER_VALUE "The actual type of this data depends on the Parameter Type of the parameter in question";

BO_ 2181394112 WRITE_PARAMETER_150_AND_151: 8 Vector__XXX
 SG_ FIRST_PARAMETER_VALUE : 0|32@1+ (1,0) [0|0] "" Vector__XXX
 SG_ SECOND_PARAMETER_VALUE : 32|32@1+ (1,0) [0|0] "" Vector__XXX

CM_ BO_ 2181394112 "Write Parameter 150 and 151 at the same time. Two Write Parameter Response frames will be sent in response.";
CM_ SG_ 2181394112 FIRST_PARAMETER_VALUE "The actual type of this data depends on the Parameter Type of the parameter in question";
CM_ SG_ 2181394112 SECOND_PARAMETER_VALUE "The actual type of this data depends on the Parameter Type of the parameter in question";

BO_ 2181394176 WRITE_PARAMETER_152_AND_153: 8 Vector__XXX
 SG_ FIRST_PARAMETER_VALUE : 0|32@1+ (1,0) [0|0] "" Vector__XXX
 SG_ SECOND_PARAMETER_VALUE : 32|32@1+ (1,0) [0|0] "" Vector__XXX

CM_ BO_ 2181394176 "Write Parameter 152 and 153 at the same time. Two Write Parameter Response frames will be sent in response.";
CM_ SG_ 2181394176 FIRST_PARAMETER_VALUE "The actual type of this data depends on the Parameter Type of the parameter in question";
CM_ SG_ 2181394176 SECOND_PARAMETER_VALUE "The actual type of this data depends on the Parameter Type of the parameter in question";

BO_ 2181394240 WRITE_PARAMETER_154_AND_155: 8 Vector__XXX
 SG_ FIRST_PARAMETER_VALUE : 0|32@1+ (1,0) [0|0] "" Vector__XXX
 SG_ SECOND_PARAMETER_VALUE : 32|32@1+ (1,0) [0|0] "" Vector__XXX

CM_ BO_ 2181394240 "Write Parameter 154 and 155 at the same time. Two Write Parameter Response frames will be sent in response.";
CM_ SG_ 2181394240 FIRST_PARAMETER_VALUE "The actual type of this data depends on the Parameter Type of the parameter in question";
CM_ SG_ 2181394240 SECOND_PARAMETER_VALUE "The actual type of this data depends on the Parameter Type of the parameter in question";

BO_ 2181394304 WRITE_PARAMETER_156_AND_157: 8 Vector__XXX
 SG_ FIRST_PARAMETER_VALUE : 0|32@1+ (1,0) [0|0] "" Vector__XXX
 SG_ SECOND_PARAMETER_VALUE : 32|32@1+ (1,0) [0|0] "" Vector__XXX

CM_ BO_ 2181394304 "Write Parameter 156 and 157 at the same time. Two Write Parameter Response frames will be sent in response.";
CM_ SG_ 2181394304 FIRST_PARAMETER_VALUE "The actual type of this data depends on the Parameter Type of the parameter in question";
CM_ SG_ 2181394304 SECOND_PARAMETER_VALUE "The actual type of this data depends on the Parameter Type of the parameter in question";

BO_ 2181394368 WRITE_PARAMETER_158_AND_159: 8 Vector__XXX
 SG_ FIRST_PARAMETER_VALUE : 0|32@1+ (1,0) [0|0] "" Vector__XXX
 SG_ SECOND_PARAMETER_VALUE : 32|32@1+ (1,0) [0|0] "" Vector__XXX

CM_ BO_ 2181394368 "Write Parameter 158 and 159 at the same time. Two Write Parameter Response frames will be sent in response.";
CM_ SG_ 2181394368 FIRST_PARAMETER_VALUE "The actual type of this data depends on the Parameter Type of the parameter in question";
CM_ SG_ 2181394368 SECOND_PARAMETER_VALUE "The actual type of this data depends on the Parameter Type of the parameter in question";

BO_ 2181394432 WRITE_PARAMETER_160_AND_161: 8 Vector__XXX
 SG_ FIRST_PARAMETER_VALUE : 0|32@1+ (1,0) [0|0] "" Vector__XXX
 SG_ SECOND_PARAMETER_VALUE : 32|32@1+ (1,0) [0|0] "" Vector__XXX

CM_ BO_ 2181394432 "Write Parameter 160 and 161 at the same time. Two Write Parameter Response frames will be sent in response.";
CM_ SG_ 2181394432 FIRST_PARAMETER_VALUE "The actual type of this data depends on the Parameter Type of the parameter in question";
CM_ SG_ 2181394432 SECOND_PARAMETER_VALUE "The actual type of this data depends on the Parameter Type of the parameter in question";

BO_ 2181394496 WRITE_PARAMETER_162_AND_163: 8 Vector__XXX
 SG_ FIRST_PARAMETER_VALUE : 0|32@1+ (1,0) [0|0] "" Vector__XXX
 SG_ SECOND_PARAMETER_VALUE : 32|32@1+ (1,0) [0|0] "" Vector__XXX

CM_ BO_ 2181394496 "Write Parameter 162 and 163 at the same time. Two Write Parameter Response frames will be sent in response.";
CM_ SG_ 2181394496 FIRST_PARAMETER_VALUE "The actual type of this data depends on the Parameter Type of the parameter in question";
CM_ SG_ 2181394496 SECOND_PARAMETER_VALUE "The actual type of this data depends on the Parameter Type of the parameter in question";

BO_ 2181394560 WRITE_PARAMETER_164_AND_165: 8 Vector__XXX
 SG_ FIRST_PARAMETER_VALUE : 0|32@1+ (1,0) [0|0] "" Vector__XXX
 SG_ SECOND_PARAMETER_VALUE : 32|32@1+ (1,0) [0|0] "" Vector__XXX

CM_ BO_ 2181394560 "Write Parameter 164 and 165 at the same time. Two Write Parameter Response frames will be sent in response.";
CM_ SG_ 2181394560 FIRST_PARAMETER_VALUE "The actual type of this data depends on the Parameter Type of the parameter in question";
CM_ SG_ 2181394560 SECOND_PARAMETER_VALUE "The actual type of this data depends on the Parameter Type of the parameter in question";

BO_ 2181394624 WRITE_PARAMETER_166_AND_167: 8 Vector__XXX
 SG_ FIRST_PARAMETER_VALUE : 0|32@1+ (1,0) [0|0] "" Vector__XXX
 SG_ SECOND_PARAMETER_VALUE : 32|32@1+ (1,0) [0|0] "" Vector__XXX

CM_ BO_ 2181394624 "Write Parameter 166 and 167 at the same time. Two Write Parameter Response frames will be sent in response.";
CM_ SG_ 2181394624 FIRST_PARAMETER_VALUE "The actual type of this data depends on the Parameter Type of the parameter in question";
CM_ SG_ 2181394624 SECOND_PARAMETER_VALUE "The actual type of this data depends on the Parameter Type of the parameter in question";

BO_ 2181394688 WRITE_PARAMETER_168_AND_169: 8 Vector__XXX
 SG_ FIRST_PARAMETER_VALUE : 0|32@1+ (1,0) [0|0] "" Vector__XXX
 SG_ SECOND_PARAMETER_VALUE : 32|32@1+ (1,0) [0|0] "" Vector__XXX

CM_ BO_ 2181394688 "Write Parameter 168 and 169 at the same time. Two Write Parameter Response frames will be sent in response.";
CM_ SG_ 2181394688 FIRST_PARAMETER_VALUE "The actual type of this data depends on the Parameter Type of the parameter in question";
CM_ SG_ 2181394688 SECOND_PARAMETER_VALUE "The actual type of this data depends on the Parameter Type of the parameter in question";

BO_ 2181394752 WRITE_PARAMETER_170_AND_171: 8 Vector__XXX
 SG_ FIRST_PARAMETER_VALUE : 0|32@1+ (1,0) [0|0] "" Vector__XXX
 SG_ SECOND_PARAMETER_VALUE : 32|32@1+ (1,0) [0|0] "" Vector__XXX

CM_ BO_ 2181394752 "Write Parameter 170 and 171 at the same time. Two Write Parameter Response frames will be sent in response.";
CM_ SG_ 2181394752 FIRST_PARAMETER_VALUE "The actual type of this data depends on the Parameter Type of the parameter in question";
CM_ SG_ 2181394752 SECOND_PARAMETER_VALUE "The actual type of this data depends on the Parameter Type of the parameter in question";

BO_ 2181394816 WRITE_PARAMETER_172_AND_173: 8 Vector__XXX
 SG_ FIRST_PARAMETER_VALUE : 0|32@1+ (1,0) [0|0] "" Vector__XXX
 SG_ SECOND_PARAMETER_VALUE : 32|32@1+ (1,0) [0|0] "" Vector__XXX

CM_ BO_ 2181394816 "Write Parameter 172 and 173 at the same time. Two Write Parameter Response frames will be sent in response.";
CM_ SG_ 2181394816 FIRST_PARAMETER_VALUE "The actual type of this data depends on the Parameter Type of the parameter in question";
CM_ SG_ 2181394816 SECOND_PARAMETER_VALUE "The actual type of this data depends on the Parameter Type of the parameter in question";

BO_ 2181394880 WRITE_PARAMETER_174_AND_175: 8 Vector__XXX
 SG_ FIRST_PARAMETER_VALUE : 0|32@1+ (1,0) [0|0] "" Vector__XXX
 SG_ SECOND_PARAMETER_VALUE : 32|32@1+ (1,0) [0|0] "" Vector__XXX

CM_ BO_ 2181394880 "Write Parameter 174 and 175 at the same time. Two Write Parameter Response frames will be sent in response.";
CM_ SG_ 2181394880 FIRST_PARAMETER_VALUE "The actual type of this data depends on the Parameter Type of the parameter in question";
CM_ SG_ 2181394880 SECOND_PARAMETER_VALUE "The actual type of this data depends on the Parameter Type of the parameter in question";

BO_ 2181394944 WRITE_PARAMETER_176_AND_177: 8 Vector__XXX
 SG_ FIRST_PARAMETER_VALUE : 0|32@1+ (1,0) [0|0] "" Vector__XXX
 SG_ SECOND_PARAMETER_VALUE : 32|32@1+ (1,0) [0|0] "" Vector__XXX

CM_ BO_ 2181394944 "Write Parameter 176 and 177 at the same time. Two Write Parameter Response frames will be sent in response.";
CM_ SG_ 2181394944 FIRST_PARAMETER_VALUE "The actual type of this data depends on the Parameter Type of the parameter in question";
CM_ SG_ 2181394944 SECOND_PARAMETER_VALUE "The actual type of this data depends on the Parameter Type of the parameter in question";

BO_ 2181395008 WRITE_PARAMETER_178_AND_179: 8 Vector__XXX
 SG_ FIRST_PARAMETER_VALUE : 0|32@1+ (1,0) [0|0] "" Vector__XXX
 SG_ SECOND_PARAMETER_VALUE : 32|32@1+ (1,0) [0|0] "" Vector__XXX

CM_ BO_ 2181395008 "Write Parameter 178 and 179 at the same time. Two Write Parameter Response frames will be sent in response.";
CM_ SG_ 2181395008 FIRST_PARAMETER_VALUE "The actual type of this data depends on the Parameter Type of the parameter in question";
CM_ SG_ 2181395008 SECOND_PARAMETER_VALUE "The actual type of this data depends on the Parameter Type of the parameter in question";

BO_ 2181395072 WRITE_PARAMETER_180_AND_181: 8 Vector__XXX
 SG_ FIRST_PARAMETER_VALUE : 0|32@1+ (1,0) [0|0] "" Vector__XXX
 SG_ SECOND_PARAMETER_VALUE : 32|32@1+ (1,0) [0|0] "" Vector__XXX

CM_ BO_ 2181395072 "Write Parameter 180 and 181 at the same time. Two Write Parameter Response frames will be sent in response.";
CM_ SG_ 2181395072 FIRST_PARAMETER_VALUE "The actual type of this data depends on the Parameter Type of the parameter in question";
CM_ SG_ 2181395072 SECOND_PARAMETER_VALUE "The actual type of this data depends on the Parameter Type of the parameter in question";

BO_ 2181395136 WRITE_PARAMETER_182_AND_183: 8 Vector__XXX
 SG_ FIRST_PARAMETER_VALUE : 0|32@1+ (1,0) [0|0] "" Vector__XXX
 SG_ SECOND_PARAMETER_VALUE : 32|32@1+ (1,0) [0|0] "" Vector__XXX

CM_ BO_ 2181395136 "Write Parameter 182 and 183 at the same time. Two Write Parameter Response frames will be sent in response.";
CM_ SG_ 2181395136 FIRST_PARAMETER_VALUE "The actual type of this data depends on the Parameter Type of the parameter in question";
CM_ SG_ 2181395136 SECOND_PARAMETER_VALUE "The actual type of this data depends on the Parameter Type of the parameter in question";

BO_ 2181395200 WRITE_PARAMETER_184_AND_185: 8 Vector__XXX
 SG_ FIRST_PARAMETER_VALUE : 0|32@1+ (1,0) [0|0] "" Vector__XXX
 SG_ SECOND_PARAMETER_VALUE : 32|32@1+ (1,0) [0|0] "" Vector__XXX

CM_ BO_ 2181395200 "Write Parameter 184 and 185 at the same time. Two Write Parameter Response frames will be sent in response.";
CM_ SG_ 2181395200 FIRST_PARAMETER_VALUE "The actual type of this data depends on the Parameter Type of the parameter in question";
CM_ SG_ 2181395200 SECOND_PARAMETER_VALUE "The actual type of this data depends on the Parameter Type of the parameter in question";

BO_ 2181395264 WRITE_PARAMETER_186_AND_187: 8 Vector__XXX
 SG_ FIRST_PARAMETER_VALUE : 0|32@1+ (1,0) [0|0] "" Vector__XXX
 SG_ SECOND_PARAMETER_VALUE : 32|32@1+ (1,0) [0|0] "" Vector__XXX

CM_ BO_ 2181395264 "Write Parameter 186 and 187 at the same time. Two Write Parameter Response frames will be sent in response.";
CM_ SG_ 2181395264 FIRST_PARAMETER_VALUE "The actual type of this data depends on the Parameter Type of the parameter in question";
CM_ SG_ 2181395264 SECOND_PARAMETER_VALUE "The actual type of this data depends on the Parameter Type of the parameter in question";

BO_ 2181395328 WRITE_PARAMETER_188_AND_189: 8 Vector__XXX
 SG_ FIRST_PARAMETER_VALUE : 0|32@1+ (1,0) [0|0] "" Vector__XXX
 SG_ SECOND_PARAMETER_VALUE : 32|32@1+ (1,0) [0|0] "" Vector__XXX

CM_ BO_ 2181395328 "Write Parameter 188 and 189 at the same time. Two Write Parameter Response frames will be sent in response.";
CM_ SG_ 2181395328 FIRST_PARAMETER_VALUE "The actual type of this data depends on the Parameter Type of the parameter in question";
CM_ SG_ 2181395328 SECOND_PARAMETER_VALUE "The actual type of this data depends on the Parameter Type of the parameter in question";

BO_ 2181395392 WRITE_PARAMETER_190_AND_191: 8 Vector__XXX
 SG_ FIRST_PARAMETER_VALUE : 0|32@1+ (1,0) [0|0] "" Vector__XXX
 SG_ SECOND_PARAMETER_VALUE : 32|32@1+ (1,0) [0|0] "" Vector__XXX

CM_ BO_ 2181395392 "Write Parameter 190 and 191 at the same time. Two Write Parameter Response frames will be sent in response.";
CM_ SG_ 2181395392 FIRST_PARAMETER_VALUE "The actual type of this data depends on the Parameter Type of the parameter in question";
CM_ SG_ 2181395392 SECOND_PARAMETER_VALUE "The actual type of this data depends on the Parameter Type of the parameter in question";

BO_ 2181395456 WRITE_PARAMETER_192_AND_193: 8 Vector__XXX
 SG_ FIRST_PARAMETER_VALUE : 0|32@1+ (1,0) [0|0] "" Vector__XXX
 SG_ SECOND_PARAMETER_VALUE : 32|32@1+ (1,0) [0|0] "" Vector__XXX

CM_ BO_ 2181395456 "Write Parameter 192 and 193 at the same time. Two Write Parameter Response frames will be sent in response.";
CM_ SG_ 2181395456 FIRST_PARAMETER_VALUE "The actual type of this data depends on the Parameter Type of the parameter in question";
CM_ SG_ 2181395456 SECOND_PARAMETER_VALUE "The actual type of this data depends on the Parameter Type of the parameter in question";

BO_ 2181395520 WRITE_PARAMETER_194_AND_195: 8 Vector__XXX
 SG_ FIRST_PARAMETER_VALUE : 0|32@1+ (1,0) [0|0] "" Vector__XXX
 SG_ SECOND_PARAMETER_VALUE : 32|32@1+ (1,0) [0|0] "" Vector__XXX

CM_ BO_ 2181395520 "Write Parameter 194 and 195 at the same time. Two Write Parameter Response frames will be sent in response.";
CM_ SG_ 2181395520 FIRST_PARAMETER_VALUE "The actual type of this data depends on the Parameter Type of the parameter in question";
CM_ SG_ 2181395520 SECOND_PARAMETER_VALUE "The actual type of this data depends on the Parameter Type of the parameter in question";

BO_ 2181395584 WRITE_PARAMETER_196_AND_197: 8 Vector__XXX
 SG_ FIRST_PARAMETER_VALUE : 0|32@1+ (1,0) [0|0] "" Vector__XXX
 SG_ SECOND_PARAMETER_VALUE : 32|32@1+ (1,0) [0|0] "" Vector__XXX

CM_ BO_ 2181395584 "Write Parameter 196 and 197 at the same time. Two Write Parameter Response frames will be sent in response.";
CM_ SG_ 2181395584 FIRST_PARAMETER_VALUE "The actual type of this data depends on the Parameter Type of the parameter in question";
CM_ SG_ 2181395584 SECOND_PARAMETER_VALUE "The actual type of this data depends on the Parameter Type of the parameter in question";

BO_ 2181395648 WRITE_PARAMETER_198_AND_199: 8 Vector__XXX
 SG_ FIRST_PARAMETER_VALUE : 0|32@1+ (1,0) [0|0] "" Vector__XXX
 SG_ SECOND_PARAMETER_VALUE : 32|32@1+ (1,0) [0|0] "" Vector__XXX

CM_ BO_ 2181395648 "Write Parameter 198 and 199 at the same time. Two Write Parameter Response frames will be sent in response.";
CM_ SG_ 2181395648 FIRST_PARAMETER_VALUE "The actual type of this data depends on the Parameter Type of the parameter in question";
CM_ SG_ 2181395648 SECOND_PARAMETER_VALUE "The actual type of this data depends on the Parameter Type of the parameter in question";

BO_ 2181395712 WRITE_PARAMETER_200_AND_201: 8 Vector__XXX
 SG_ FIRST_PARAMETER_VALUE : 0|32@1+ (1,0) [0|0] "" Vector__XXX
 SG_ SECOND_PARAMETER_VALUE : 32|32@1+ (1,0) [0|0] "" Vector__XXX

CM_ BO_ 2181395712 "Write Parameter 200 and 201 at the same time. Two Write Parameter Response frames will be sent in response.";
CM_ SG_ 2181395712 FIRST_PARAMETER_VALUE "The actual type of this data depends on the Parameter Type of the parameter in question";
CM_ SG_ 2181395712 SECOND_PARAMETER_VALUE "The actual type of this data depends on the Parameter Type of the parameter in question";

BO_ 2181395776 WRITE_PARAMETER_202_AND_203: 8 Vector__XXX
 SG_ FIRST_PARAMETER_VALUE : 0|32@1+ (1,0) [0|0] "" Vector__XXX
 SG_ SECOND_PARAMETER_VALUE : 32|32@1+ (1,0) [0|0] "" Vector__XXX

CM_ BO_ 2181395776 "Write Parameter 202 and 203 at the same time. Two Write Parameter Response frames will be sent in response.";
CM_ SG_ 2181395776 FIRST_PARAMETER_VALUE "The actual type of this data depends on the Parameter Type of the parameter in question";
CM_ SG_ 2181395776 SECOND_PARAMETER_VALUE "The actual type of this data depends on the Parameter Type of the parameter in question";

BO_ 2181395840 WRITE_PARAMETER_204_AND_205: 8 Vector__XXX
 SG_ FIRST_PARAMETER_VALUE : 0|32@1+ (1,0) [0|0] "" Vector__XXX
 SG_ SECOND_PARAMETER_VALUE : 32|32@1+ (1,0) [0|0] "" Vector__XXX

CM_ BO_ 2181395840 "Write Parameter 204 and 205 at the same time. Two Write Parameter Response frames will be sent in response.";
CM_ SG_ 2181395840 FIRST_PARAMETER_VALUE "The actual type of this data depends on the Parameter Type of the parameter in question";
CM_ SG_ 2181395840 SECOND_PARAMETER_VALUE "The actual type of this data depends on the Parameter Type of the parameter in question";

BO_ 2181395904 WRITE_PARAMETER_206_AND_207: 8 Vector__XXX
 SG_ FIRST_PARAMETER_VALUE : 0|32@1+ (1,0) [0|0] "" Vector__XXX
 SG_ SECOND_PARAMETER_VALUE : 32|32@1+ (1,0) [0|0] "" Vector__XXX

CM_ BO_ 2181395904 "Write Parameter 206 and 207 at the same time. Two Write Parameter Response frames will be sent in response.";
CM_ SG_ 2181395904 FIRST_PARAMETER_VALUE "The actual type of this data depends on the Parameter Type of the parameter in question";
CM_ SG_ 2181395904 SECOND_PARAMETER_VALUE "The actual type of this data depends on the Parameter Type of the parameter in question";

BO_ 2181395968 WRITE_PARAMETER_208_AND_209: 8 Vector__XXX
 SG_ FIRST_PARAMETER_VALUE : 0|32@1+ (1,0) [0|0] "" Vector__XXX
 SG_ SECOND_PARAMETER_VALUE : 32|32@1+ (1,0) [0|0] "" Vector__XXX

CM_ BO_ 2181395968 "Write Parameter 208 and 209 at the same time. Two Write Parameter Response frames will be sent in response.";
CM_ SG_ 2181395968 FIRST_PARAMETER_VALUE "The actual type of this data depends on the Parameter Type of the parameter in question";
CM_ SG_ 2181395968 SECOND_PARAMETER_VALUE "The actual type of this data depends on the Parameter Type of the parameter in question";

BO_ 2181396032 WRITE_PARAMETER_210_AND_211: 8 Vector__XXX
 SG_ FIRST_PARAMETER_VALUE : 0|32@1+ (1,0) [0|0] "" Vector__XXX
 SG_ SECOND_PARAMETER_VALUE : 32|32@1+ (1,0) [0|0] "" Vector__XXX

CM_ BO_ 2181396032 "Write Parameter 210 and 211 at the same time. Two Write Parameter Response frames will be sent in response.";
CM_ SG_ 2181396032 FIRST_PARAMETER_VALUE "The actual type of this data depends on the Parameter Type of the parameter in question";
CM_ SG_ 2181396032 SECOND_PARAMETER_VALUE "The actual type of this data depends on the Parameter Type of the parameter in question";

BO_ 2181396096 WRITE_PARAMETER_212_AND_213: 8 Vector__XXX
 SG_ FIRST_PARAMETER_VALUE : 0|32@1+ (1,0) [0|0] "" Vector__XXX
 SG_ SECOND_PARAMETER_VALUE : 32|32@1+ (1,0) [0|0] "" Vector__XXX

CM_ BO_ 2181396096 "Write Parameter 212 and 213 at the same time. Two Write Parameter Response frames will be sent in response.";
CM_ SG_ 2181396096 FIRST_PARAMETER_VALUE "The actual type of this data depends on the Parameter Type of the parameter in question";
CM_ SG_ 2181396096 SECOND_PARAMETER_VALUE "The actual type of this data depends on the Parameter Type of the parameter in question";

BO_ 2181396160 WRITE_PARAMETER_214_AND_215: 8 Vector__XXX
 SG_ FIRST_PARAMETER_VALUE : 0|32@1+ (1,0) [0|0] "" Vector__XXX
 SG_ SECOND_PARAMETER_VALUE : 32|32@1+ (1,0) [0|0] "" Vector__XXX

CM_ BO_ 2181396160 "Write Parameter 214 and 215 at the same time. Two Write Parameter Response frames will be sent in response.";
CM_ SG_ 2181396160 FIRST_PARAMETER_VALUE "The actual type of this data depends on the Parameter Type of the parameter in question";
CM_ SG_ 2181396160 SECOND_PARAMETER_VALUE "The actual type of this data depends on the Parameter Type of the parameter in question";

BO_ 2181396224 WRITE_PARAMETER_216_AND_217: 8 Vector__XXX
 SG_ FIRST_PARAMETER_VALUE : 0|32@1+ (1,0) [0|0] "" Vector__XXX
 SG_ SECOND_PARAMETER_VALUE : 32|32@1+ (1,0) [0|0] "" Vector__XXX

CM_ BO_ 2181396224 "Write Parameter 216 and 217 at the same time. Two Write Parameter Response frames will be sent in response.";
CM_ SG_ 2181396224 FIRST_PARAMETER_VALUE "The actual type of this data depends on the Parameter Type of the parameter in question";
CM_ SG_ 2181396224 SECOND_PARAMETER_VALUE "The actual type of this data depends on the Parameter Type of the parameter in question";

BO_ 2181396288 WRITE_PARAMETER_218_AND_219: 8 Vector__XXX
 SG_ FIRST_PARAMETER_VALUE : 0|32@1+ (1,0) [0|0] "" Vector__XXX
 SG_ SECOND_PARAMETER_VALUE : 32|32@1+ (1,0) [0|0] "" Vector__XXX

CM_ BO_ 2181396288 "Write Parameter 218 and 219 at the same time. Two Write Parameter Response frames will be sent in response.";
CM_ SG_ 2181396288 FIRST_PARAMETER_VALUE "The actual type of this data depends on the Parameter Type of the parameter in question";
CM_ SG_ 2181396288 SECOND_PARAMETER_VALUE "The actual type of this data depends on the Parameter Type of the parameter in question";

BO_ 2181396352 WRITE_PARAMETER_220_AND_221: 8 Vector__XXX
 SG_ FIRST_PARAMETER_VALUE : 0|32@1+ (1,0) [0|0] "" Vector__XXX
 SG_ SECOND_PARAMETER_VALUE : 32|32@1+ (1,0) [0|0] "" Vector__XXX

CM_ BO_ 2181396352 "Write Parameter 220 and 221 at the same time. Two Write Parameter Response frames will be sent in response.";
CM_ SG_ 2181396352 FIRST_PARAMETER_VALUE "The actual type of this data depends on the Parameter Type of the parameter in question";
CM_ SG_ 2181396352 SECOND_PARAMETER_VALUE "The actual type of this data depends on the Parameter Type of the parameter in question";

BO_ 2181396416 WRITE_PARAMETER_222_AND_223: 8 Vector__XXX
 SG_ FIRST_PARAMETER_VALUE : 0|32@1+ (1,0) [0|0] "" Vector__XXX
 SG_ SECOND_PARAMETER_VALUE : 32|32@1+ (1,0) [0|0] "" Vector__XXX

CM_ BO_ 2181396416 "Write Parameter 222 and 223 at the same time. Two Write Parameter Response frames will be sent in response.";
CM_ SG_ 2181396416 FIRST_PARAMETER_VALUE "The actual type of this data depends on the Parameter Type of the parameter in question";
CM_ SG_ 2181396416 SECOND_PARAMETER_VALUE "The actual type of this data depends on the Parameter Type of the parameter in question";

BO_ 2181396480 WRITE_PARAMETER_224_AND_225: 8 Vector__XXX
 SG_ FIRST_PARAMETER_VALUE : 0|32@1+ (1,0) [0|0] "" Vector__XXX
 SG_ SECOND_PARAMETER_VALUE : 32|32@1+ (1,0) [0|0] "" Vector__XXX

CM_ BO_ 2181396480 "Write Parameter 224 and 225 at the same time. Two Write Parameter Response frames will be sent in response.";
CM_ SG_ 2181396480 FIRST_PARAMETER_VALUE "The actual type of this data depends on the Parameter Type of the parameter in question";
CM_ SG_ 2181396480 SECOND_PARAMETER_VALUE "The actual type of this data depends on the Parameter Type of the parameter in question";

BO_ 2181396544 WRITE_PARAMETER_226_AND_227: 8 Vector__XXX
 SG_ FIRST_PARAMETER_VALUE : 0|32@1+ (1,0) [0|0] "" Vector__XXX
 SG_ SECOND_PARAMETER_VALUE : 32|32@1+ (1,0) [0|0] "" Vector__XXX

CM_ BO_ 2181396544 "Write Parameter 226 and 227 at the same time. Two Write Parameter Response frames will be sent in response.";
CM_ SG_ 2181396544 FIRST_PARAMETER_VALUE "The actual type of this data depends on the Parameter Type of the parameter in question";
CM_ SG_ 2181396544 SECOND_PARAMETER_VALUE "The actual type of this data depends on the Parameter Type of the parameter in question";

BO_ 2181396608 WRITE_PARAMETER_228_AND_229: 8 Vector__XXX
 SG_ FIRST_PARAMETER_VALUE : 0|32@1+ (1,0) [0|0] "" Vector__XXX
 SG_ SECOND_PARAMETER_VALUE : 32|32@1+ (1,0) [0|0] "" Vector__XXX

CM_ BO_ 2181396608 "Write Parameter 228 and 229 at the same time. Two Write Parameter Response frames will be sent in response.";
CM_ SG_ 2181396608 FIRST_PARAMETER_VALUE "The actual type of this data depends on the Parameter Type of the parameter in question";
CM_ SG_ 2181396608 SECOND_PARAMETER_VALUE "The actual type of this data depends on the Parameter Type of the parameter in question";

BO_ 2181396672 WRITE_PARAMETER_230_AND_231: 8 Vector__XXX
 SG_ FIRST_PARAMETER_VALUE : 0|32@1+ (1,0) [0|0] "" Vector__XXX
 SG_ SECOND_PARAMETER_VALUE : 32|32@1+ (1,0) [0|0] "" Vector__XXX

CM_ BO_ 2181396672 "Write Parameter 230 and 231 at the same time. Two Write Parameter Response frames will be sent in response.";
CM_ SG_ 2181396672 FIRST_PARAMETER_VALUE "The actual type of this data depends on the Parameter Type of the parameter in question";
CM_ SG_ 2181396672 SECOND_PARAMETER_VALUE "The actual type of this data depends on the Parameter Type of the parameter in question";

BO_ 2181396736 WRITE_PARAMETER_232_AND_233: 8 Vector__XXX
 SG_ FIRST_PARAMETER_VALUE : 0|32@1+ (1,0) [0|0] "" Vector__XXX
 SG_ SECOND_PARAMETER_VALUE : 32|32@1+ (1,0) [0|0] "" Vector__XXX

CM_ BO_ 2181396736 "Write Parameter 232 and 233 at the same time. Two Write Parameter Response frames will be sent in response.";
CM_ SG_ 2181396736 FIRST_PARAMETER_VALUE "The actual type of this data depends on the Parameter Type of the parameter in question";
CM_ SG_ 2181396736 SECOND_PARAMETER_VALUE "The actual type of this data depends on the Parameter Type of the parameter in question";

BO_ 2181396800 WRITE_PARAMETER_234_AND_235: 8 Vector__XXX
 SG_ FIRST_PARAMETER_VALUE : 0|32@1+ (1,0) [0|0] "" Vector__XXX
 SG_ SECOND_PARAMETER_VALUE : 32|32@1+ (1,0) [0|0] "" Vector__XXX

CM_ BO_ 2181396800 "Write Parameter 234 and 235 at the same time. Two Write Parameter Response frames will be sent in response.";
CM_ SG_ 2181396800 FIRST_PARAMETER_VALUE "The actual type of this data depends on the Parameter Type of the parameter in question";
CM_ SG_ 2181396800 SECOND_PARAMETER_VALUE "The actual type of this data depends on the Parameter Type of the parameter in question";

BO_ 2181396864 WRITE_PARAMETER_236_AND_237: 8 Vector__XXX
 SG_ FIRST_PARAMETER_VALUE : 0|32@1+ (1,0) [0|0] "" Vector__XXX
 SG_ SECOND_PARAMETER_VALUE : 32|32@1+ (1,0) [0|0] "" Vector__XXX

CM_ BO_ 2181396864 "Write Parameter 236 and 237 at the same time. Two Write Parameter Response frames will be sent in response.";
CM_ SG_ 2181396864 FIRST_PARAMETER_VALUE "The actual type of this data depends on the Parameter Type of the parameter in question";
CM_ SG_ 2181396864 SECOND_PARAMETER_VALUE "The actual type of this data depends on the Parameter Type of the parameter in question";

BO_ 2181396928 WRITE_PARAMETER_238_AND_239: 8 Vector__XXX
 SG_ FIRST_PARAMETER_VALUE : 0|32@1+ (1,0) [0|0] "" Vector__XXX
 SG_ SECOND_PARAMETER_VALUE : 32|32@1+ (1,0) [0|0] "" Vector__XXX

CM_ BO_ 2181396928 "Write Parameter 238 and 239 at the same time. Two Write Parameter Response frames will be sent in response.";
CM_ SG_ 2181396928 FIRST_PARAMETER_VALUE "The actual type of this data depends on the Parameter Type of the parameter in question";
CM_ SG_ 2181396928 SECOND_PARAMETER_VALUE "The actual type of this data depends on the Parameter Type of the parameter in question";

BO_ 2181396992 WRITE_PARAMETER_240_AND_241: 8 Vector__XXX
 SG_ FIRST_PARAMETER_VALUE : 0|32@1+ (1,0) [0|0] "" Vector__XXX
 SG_ SECOND_PARAMETER_VALUE : 32|32@1+ (1,0) [0|0] "" Vector__XXX

CM_ BO_ 2181396992 "Write Parameter 240 and 241 at the same time. Two Write Parameter Response frames will be sent in response.";
CM_ SG_ 2181396992 FIRST_PARAMETER_VALUE "The actual type of this data depends on the Parameter Type of the parameter in question";
CM_ SG_ 2181396992 SECOND_PARAMETER_VALUE "The actual type of this data depends on the Parameter Type of the parameter in question";

BO_ 2181397056 WRITE_PARAMETER_242_AND_243: 8 Vector__XXX
 SG_ FIRST_PARAMETER_VALUE : 0|32@1+ (1,0) [0|0] "" Vector__XXX
 SG_ SECOND_PARAMETER_VALUE : 32|32@1+ (1,0) [0|0] "" Vector__XXX

CM_ BO_ 2181397056 "Write Parameter 242 and 243 at the same time. Two Write Parameter Response frames will be sent in response.";
CM_ SG_ 2181397056 FIRST_PARAMETER_VALUE "The actual type of this data depends on the Parameter Type of the parameter in question";
CM_ SG_ 2181397056 SECOND_PARAMETER_VALUE "The actual type of this data depends on the Parameter Type of the parameter in question";

BO_ 2181397120 WRITE_PARAMETER_244_AND_245: 8 Vector__XXX
 SG_ FIRST_PARAMETER_VALUE : 0|32@1+ (1,0) [0|0] "" Vector__XXX
 SG_ SECOND_PARAMETER_VALUE : 32|32@1+ (1,0) [0|0] "" Vector__XXX

CM_ BO_ 2181397120 "Write Parameter 244 and 245 at the same time. Two Write Parameter Response frames will be sent in response.";
CM_ SG_ 2181397120 FIRST_PARAMETER_VALUE "The actual type of this data depends on the Parameter Type of the parameter in question";
CM_ SG_ 2181397120 SECOND_PARAMETER_VALUE "The actual type of this data depends on the Parameter Type of the parameter in question";

BO_ 2181397184 WRITE_PARAMETER_246_AND_247: 8 Vector__XXX
 SG_ FIRST_PARAMETER_VALUE : 0|32@1+ (1,0) [0|0] "" Vector__XXX
 SG_ SECOND_PARAMETER_VALUE : 32|32@1+ (1,0) [0|0] "" Vector__XXX

CM_ BO_ 2181397184 "Write Parameter 246 and 247 at the same time. Two Write Parameter Response frames will be sent in response.";
CM_ SG_ 2181397184 FIRST_PARAMETER_VALUE "The actual type of this data depends on the Parameter Type of the parameter in question";
CM_ SG_ 2181397184 SECOND_PARAMETER_VALUE "The actual type of this data depends on the Parameter Type of the parameter in question";

BO_ 2181397248 WRITE_PARAMETER_248_AND_249: 8 Vector__XXX
 SG_ FIRST_PARAMETER_VALUE : 0|32@1+ (1,0) [0|0] "" Vector__XXX
 SG_ SECOND_PARAMETER_VALUE : 32|32@1+ (1,0) [0|0] "" Vector__XXX

CM_ BO_ 2181397248 "Write Parameter 248 and 249 at the same time. Two Write Parameter Response frames will be sent in response.";
CM_ SG_ 2181397248 FIRST_PARAMETER_VALUE "The actual type of this data depends on the Parameter Type of the parameter in question";
CM_ SG_ 2181397248 SECOND_PARAMETER_VALUE "The actual type of this data depends on the Parameter Type of the parameter in question";

BO_ 2181397312 WRITE_PARAMETER_250_AND_251: 8 Vector__XXX
 SG_ FIRST_PARAMETER_VALUE : 0|32@1+ (1,0) [0|0] "" Vector__XXX
 SG_ SECOND_PARAMETER_VALUE : 32|32@1+ (1,0) [0|0] "" Vector__XXX

CM_ BO_ 2181397312 "Write Parameter 250 and 251 at the same time. Two Write Parameter Response frames will be sent in response.";
CM_ SG_ 2181397312 FIRST_PARAMETER_VALUE "The actual type of this data depends on the Parameter Type of the parameter in question";
CM_ SG_ 2181397312 SECOND_PARAMETER_VALUE "The actual type of this data depends on the Parameter Type of the parameter in question";

BO_ 2181397376 WRITE_PARAMETER_252_AND_253: 8 Vector__XXX
 SG_ FIRST_PARAMETER_VALUE : 0|32@1+ (1,0) [0|0] "" Vector__XXX
 SG_ SECOND_PARAMETER_VALUE : 32|32@1+ (1,0) [0|0] "" Vector__XXX

CM_ BO_ 2181397376 "Write Parameter 252 and 253 at the same time. Two Write Parameter Response frames will be sent in response.";
CM_ SG_ 2181397376 FIRST_PARAMETER_VALUE "The actual type of this data depends on the Parameter Type of the parameter in question";
CM_ SG_ 2181397376 SECOND_PARAMETER_VALUE "The actual type of this data depends on the Parameter Type of the parameter in question";

BO_ 2181397440 WRITE_PARAMETER_254_AND_255: 8 Vector__XXX
 SG_ FIRST_PARAMETER_VALUE : 0|32@1+ (1,0) [0|0] "" Vector__XXX
 SG_ SECOND_PARAMETER_VALUE : 32|32@1+ (1,0) [0|0] "" Vector__XXX

CM_ BO_ 2181397440 "Write Parameter 254 and 255 at the same time. Two Write Parameter Response frames will be sent in response.";
CM_ SG_ 2181397440 FIRST_PARAMETER_VALUE "The actual type of this data depends on the Parameter Type of the parameter in question";
CM_ SG_ 2181397440 SECOND_PARAMETER_VALUE "The actual type of this data depends on the Parameter Type of the parameter in question";

BO_ 2181397504 START_FOLLOWER_MODE: 0 Vector__XXX

CM_ BO_ 2181397504 "Starts follower mode. The relevant parameters must already be configured. In response, a Start Follower Mode Response frame will be sent. Follower mode will be auto-started on boot if the Follower Mode Leader ID parameter is set to a non-zero value.";

BO_ 2181397568 START_FOLLOWER_MODE_RESPONSE: 1 Vector__XXX
 SG_ STATUS : 0|8@1+ (1,0) [0|0] "" Vector__XXX

CM_ BO_ 2181397568 "Response for a Start Follower Mode command";
CM_ SG_ 2181397568 STATUS "0 for success. 1 for invalid parameters";

BO_ 2181397632 STOP_FOLLOWER_MODE: 0 Vector__XXX

CM_ BO_ 2181397632 "Exits follower mode and causes the device to resume listening for setpoints addressed directly to it. In response, a Stop Follower Mode Response frame will be sent.";

BO_ 2181397696 STOP_FOLLOWER_MODE_RESPONSE: 0 Vector__XXX

CM_ BO_ 2181397696 "Response for a Stop Follower Mode Command";

BO_ 2181398464 ENTER_SWDL_CAN_BOOTLOADER: 0 Vector__XXX

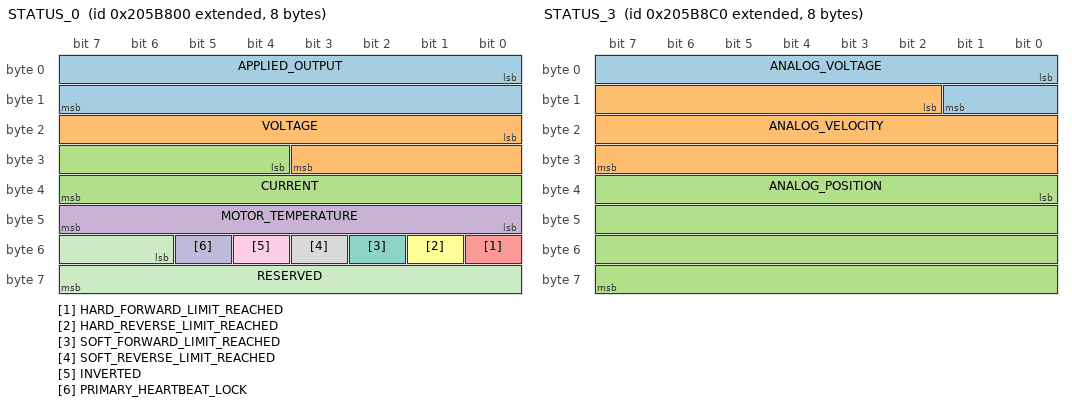
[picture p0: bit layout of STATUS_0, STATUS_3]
BO_ 2181412864 STATUS_0: 8 Vector__XXX
 SG_ APPLIED_OUTPUT : 0|16@1- (0.00003082369457075716,0) [-1|1] "" Vector__XXX
 SG_ VOLTAGE : 16|12@1+ (0.0073260073260073,0) [0|0] "V" Vector__XXX
 SG_ CURRENT : 28|12@1+ (0.0366300366300366,0) [0|0] "A" Vector__XXX
 SG_ MOTOR_TEMPERATURE : 40|8@1+ (1,0) [0|0] "degC" Vector__XXX
 SG_ HARD_FORWARD_LIMIT_REACHED : 48|1@1+ (1,0) [0|0] "" Vector__XXX
 SG_ HARD_REVERSE_LIMIT_REACHED : 49|1@1+ (1,0) [0|0] "" Vector__XXX
 SG_ SOFT_FORWARD_LIMIT_REACHED : 50|1@1+ (1,0) [0|0] "" Vector__XXX
 SG_ SOFT_REVERSE_LIMIT_REACHED : 51|1@1+ (1,0) [0|0] "" Vector__XXX
 SG_ INVERTED : 52|1@1+ (1,0) [0|0] "" Vector__XXX
 SG_ PRIMARY_HEARTBEAT_LOCK : 53|1@1+ (1,0) [0|0] "" Vector__XXX
 SG_ RESERVED : 54|10@1+ (1,0) [0|0] "" Vector__XXX

CM_ BO_ 2181412864 "Includes general data that is likely to need frequent refreshing";
CM_ SG_ 2181412864 HARD_FORWARD_LIMIT_REACHED "Whether the forward physical limit switch has been reached";
CM_ SG_ 2181412864 HARD_REVERSE_LIMIT_REACHED "Whether the reverse physical limit switch has been reached";
CM_ SG_ 2181412864 SOFT_FORWARD_LIMIT_REACHED "Whether the forward software-defined position limit has been reached";
CM_ SG_ 2181412864 SOFT_REVERSE_LIMIT_REACHED "Whether the reverse software-defined position limit has been reached";
CM_ SG_ 2181412864 PRIMARY_HEARTBEAT_LOCK "Indicates that the SPARK is in competition mode and will ignore the Secondary Heartbeat until it is power cycled";

BO_ 2181412928 STATUS_1: 8 Vector__XXX
 SG_ OTHER_FAULT : 0|1@1+ (1,0) [0|0] "" Vector__XXX
 SG_ MOTOR_TYPE_FAULT : 1|1@1+ (1,0) [0|0] "" Vector__XXX
 SG_ SENSOR_FAULT : 2|1@1+ (1,0) [0|0] "" Vector__XXX
 SG_ CAN_FAULT : 3|1@1+ (1,0) [0|0] "" Vector__XXX
 SG_ TEMPERATURE_FAULT : 4|1@1+ (1,0) [0|0] "" Vector__XXX
 SG_ DRV_FAULT : 5|1@1+ (1,0) [0|0] "" Vector__XXX
 SG_ ESC_EEPROM_FAULT : 6|1@1+ (1,0) [0|0] "" Vector__XXX
 SG_ FIRMWARE_FAULT : 7|1@1+ (1,0) [0|0] "" Vector__XXX
 SG_ RESERVED_ACTIVES : 8|8@1+ (1,0) [0|0] "" Vector__XXX
 SG_ BROWNOUT_WARNING : 16|1@1+ (1,0) [0|0] "" Vector__XXX
 SG_ OVERCURRENT_WARNING : 17|1@1+ (1,0) [0|0] "" Vector__XXX
 SG_ ESC_EEPROM_WARNING : 18|1@1+ (1,0) [0|0] "" Vector__XXX
 SG_ EXT_EEPROM_WARNING : 19|1@1+ (1,0) [0|0] "" Vector__XXX
 SG_ SENSOR_WARNING : 20|1@1+ (1,0) [0|0] "" Vector__XXX
 SG_ STALL_WARNING : 21|1@1+ (1,0) [0|0] "" Vector__XXX
 SG_ HAS_RESET_WARNING : 22|1@1+ (1,0) [0|0] "" Vector__XXX
 SG_ OTHER_WARNING : 23|1@1+ (1,0) [0|0] "" Vector__XXX
 SG_ OTHER_STICKY_FAULT : 24|1@1+ (1,0) [0|0] "" Vector__XXX
 SG_ MOTOR_TYPE_STICKY_FAULT : 25|1@1+ (1,0) [0|0] "" Vector__XXX
 SG_ SENSOR_STICKY_FAULT : 26|1@1+ (1,0) [0|0] "" Vector__XXX
 SG_ CAN_STICKY_FAULT : 27|1@1+ (1,0) [0|0] "" Vector__XXX
 SG_ TEMPERATURE_STICKY_FAULT : 28|1@1+ (1,0) [0|0] "" Vector__XXX
 SG_ DRV_STICKY_FAULT : 29|1@1+ (1,0) [0|0] "" Vector__XXX
 SG_ ESC_EEPROM_STICKY_FAULT : 30|1@1+ (1,0) [0|0] "" Vector__XXX
 SG_ FIRMWARE_STICKY_FAULT : 31|1@1+ (1,0) [0|0] "" Vector__XXX
 SG_ RESERVED_STICKIES : 32|8@1+ (1,0) [0|0] "" Vector__XXX
 SG_ BROWNOUT_STICKY_WARNING : 40|1@1+ (1,0) [0|0] "" Vector__XXX
 SG_ OVERCURRENT_STICKY_WARNING : 41|1@1+ (1,0) [0|0] "" Vector__XXX
 SG_ ESC_EEPROM_STICKY_WARNING : 42|1@1+ (1,0) [0|0] "" Vector__XXX
 SG_ EXT_EEPROM_STICKY_WARNING : 43|1@1+ (1,0) [0|0] "" Vector__XXX
 SG_ SENSOR_STICKY_WARNING : 44|1@1+ (1,0) [0|0] "" Vector__XXX
 SG_ STALL_STICKY_WARNING : 45|1@1+ (1,0) [0|0] "" Vector__XXX
 SG_ HAS_RESET_STICKY_WARNING : 46|1@1+ (1,0) [0|0] "" Vector__XXX
 SG_ OTHER_STICKY_WARNING : 47|1@1+ (1,0) [0|0] "" Vector__XXX
 SG_ IS_FOLLOWER : 48|1@1+ (1,0) [0|0] "" Vector__XXX
 SG_ RESERVED : 49|15@1+ (1,0) [0|0] "" Vector__XXX

CM_ BO_ 2181412928 "Includes general data that can likely tolerate infrequent refreshing";
CM_ SG_ 2181412928 RESERVED_ACTIVES "Reserved space for future active (non-sticky) faults and warnings";
CM_ SG_ 2181412928 RESERVED_STICKIES "Reserved space for future sticky faults and warnings";

BO_ 2181412992 STATUS_2: 8 Vector__XXX
 SG_ PRIMARY_ENCODER_VELOCITY : 0|32@1- (1,0) [0|0] "" Vector__XXX
 SG_ PRIMARY_ENCODER_POSITION : 32|32@1- (1,0) [0|0] "" Vector__XXX

CM_ BO_ 2181412992 "Includes data from the primary encoder (either a brushless motor's internal encoder, or the primary encoder associated with a brushed motor)";
CM_ SG_ 2181412992 PRIMARY_ENCODER_VELOCITY "By default, the unit is RPM, but it can be changed implicitly using the Velocity Conversion Factor parameter";
CM_ SG_ 2181412992 PRIMARY_ENCODER_POSITION "By default, the unit is rotations, but it can be changed implicitly using the Position Conversion Factor parameter";
SIG_VALTYPE_ 2181412992 PRIMARY_ENCODER_VELOCITY : 1;
SIG_VALTYPE_ 2181412992 PRIMARY_ENCODER_POSITION : 1;

BO_ 2181413056 STATUS_3: 8 Vector__XXX
 SG_ ANALOG_VOLTAGE : 0|10@1+ (0.0048973607038123,0) [0|5] "V" Vector__XXX
 SG_ ANALOG_VELOCITY : 10|22@1- (0.007812026887906498,0) [0|0] "" Vector__XXX
 SG_ ANALOG_POSITION : 32|32@1- (1,0) [0|0] "" Vector__XXX

CM_ BO_ 2181413056 "Includes data from an analog sensor";
CM_ SG_ 2181413056 ANALOG_VELOCITY "By default, the unit is RPM, but it can be changed implicitly using the Analog Velocity Conversion Factor parameter";
CM_ SG_ 2181413056 ANALOG_POSITION "By default, the unit is rotations, but it can be changed implicitly using the Analog Position Conversion Factor parameter";
SIG_VALTYPE_ 2181413056 ANALOG_POSITION : 1;

BO_ 2181413120 STATUS_4: 8 Vector__XXX
 SG_ EXTERNAL_OR_ALT_ENCODER_VELOCITY : 0|32@1- (1,0) [0|0] "" Vector__XXX
 SG_ EXTERNAL_OR_ALT_ENCODER_POSITION : 32|32@1- (1,0) [0|0] "" Vector__XXX

CM_ BO_ 2181413120 "Includes data from the External Encoder (on SPARK MAX, this is the Alternate Encoder)";
CM_ SG_ 2181413120 EXTERNAL_OR_ALT_ENCODER_VELOCITY "By default, the unit is RPM, but it can be changed implicitly using the External/Alternate Encoder Velocity Conversion Factor parameter";
CM_ SG_ 2181413120 EXTERNAL_OR_ALT_ENCODER_POSITION "By default, the unit is rotations, but it can be changed implicitly using the External/Alternate Encoder Position Conversion Factor parameter";
SIG_VALTYPE_ 2181413120 EXTERNAL_OR_ALT_ENCODER_VELOCITY : 1;
SIG_VALTYPE_ 2181413120 EXTERNAL_OR_ALT_ENCODER_POSITION : 1;

BO_ 2181413184 STATUS_5: 8 Vector__XXX
 SG_ DUTY_CYCLE_ENCODER_VELOCITY : 0|32@1- (1,0) [0|0] "" Vector__XXX
 SG_ DUTY_CYCLE_ENCODER_POSITION : 32|32@1- (1,0) [0|0] "" Vector__XXX

CM_ BO_ 2181413184 "Includes velocity and position data from a duty-cycle absolute encoder";
CM_ SG_ 2181413184 DUTY_CYCLE_ENCODER_VELOCITY "By default, the unit is RPM, but it can be changed implicitly using the Duty Cycle Velocity Conversion Factor parameter";
CM_ SG_ 2181413184 DUTY_CYCLE_ENCODER_POSITION "By default, the unit is rotations, but it can be changed implicitly using the Duty Cycle Position Conversion Factor parameter";
SIG_VALTYPE_ 2181413184 DUTY_CYCLE_ENCODER_VELOCITY : 1;
SIG_VALTYPE_ 2181413184 DUTY_CYCLE_ENCODER_POSITION : 1;

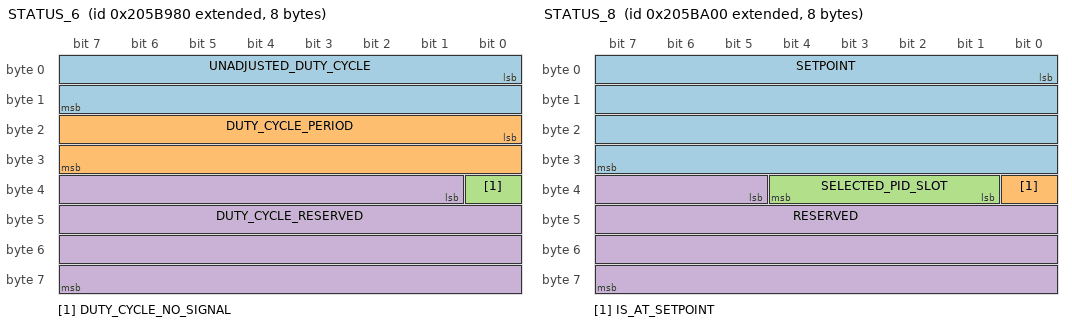
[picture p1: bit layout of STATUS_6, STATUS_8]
BO_ 2181413248 STATUS_6: 8 Vector__XXX
 SG_ UNADJUSTED_DUTY_CYCLE : 0|16@1+ (0.00001541161211566339,0) [0|1] "" Vector__XXX
 SG_ DUTY_CYCLE_PERIOD : 16|16@1+ (1,0) [0|0] "us" Vector__XXX
 SG_ DUTY_CYCLE_NO_SIGNAL : 32|1@1+ (1,0) [0|0] "" Vector__XXX
 SG_ DUTY_CYCLE_RESERVED : 33|31@1- (1,0) [0|0] "" Vector__XXX

CM_ BO_ 2181413248 "Includes other data from a duty-cycle absolute encoder";
CM_ SG_ 2181413248 UNADJUSTED_DUTY_CYCLE "The duty cycle from 0 to 1, with no inversion or conversion factor applied";

BO_ 2181413312 STATUS_7: 8 Vector__XXX
 SG_ I_ACCUMULATION : 0|32@1- (1,0) [0|0] "" Vector__XXX
 SG_ RESERVED : 32|32@1- (1,0) [0|0] "" Vector__XXX

CM_ BO_ 2181413312 "Includes diagnostic data for closed-loop control";
SIG_VALTYPE_ 2181413312 I_ACCUMULATION : 1;

BO_ 2181413376 STATUS_8: 8 Vector__XXX
 SG_ SETPOINT : 0|32@1- (1,0) [0|0] "" Vector__XXX
 SG_ IS_AT_SETPOINT : 32|1@1+ (1,0) [0|0] "" Vector__XXX
 SG_ SELECTED_PID_SLOT : 33|4@1+ (1,0) [0|0] "" Vector__XXX
 SG_ RESERVED : 37|27@1- (1,0) [0|0] "" Vector__XXX

CM_ BO_ 2181413376 "Includes additional diagnostic data for closed-loop control";
SIG_VALTYPE_ 2181413376 SETPOINT : 1;

BO_ 2181413440 STATUS_9: 8 Vector__XXX
 SG_ MAXMOTION_POSITION_SETPOINT : 0|32@1- (1,0) [0|0] "" Vector__XXX
 SG_ MAXMOTION_VELOCITY_SETPOINT : 32|32@1- (1,0) [0|0] "" Vector__XXX

CM_ BO_ 2181413440 "Includes diagnostic data for MAXMotion closed-loop control";
CM_ SG_ 2181413440 MAXMOTION_POSITION_SETPOINT "The internal, intermediate position target used by MAXMotion";
CM_ SG_ 2181413440 MAXMOTION_VELOCITY_SETPOINT "The internal, intermediate velocity target used by MAXMotion";
SIG_VALTYPE_ 2181413440 MAXMOTION_POSITION_SETPOINT : 1;
SIG_VALTYPE_ 2181413440 MAXMOTION_VELOCITY_SETPOINT : 1;

BO_ 2181413888 UNIQUE_ID_BROADCAST: 4 Vector__XXX
 SG_ UNIQUE_ID : 0|32@1+ (1,0) [0|0] "" Vector__XXX

CM_ BO_ 2181413888 "Contains the unique ID of the device, to allow detecting duplicate CAN IDs. To avoid collisions, the SPARK Flex firmware will send this at an irregular period between 1000ms and 2000ms. SPARK MAX may use a constant period of 1000ms.";

BO_ 2181431232 PERSIST_PARAMETERS: 2 Vector__XXX
 SG_ MAGIC_NUMBER : 0|16@1+ (1,0) [15011|15011] "" Vector__XXX

CM_ BO_ 2181431232 "Causes all parameters to be written to non-volatile storage. After the operation (which may take up to a second) completes, a Persist Parameters Response frame will be sent.";
